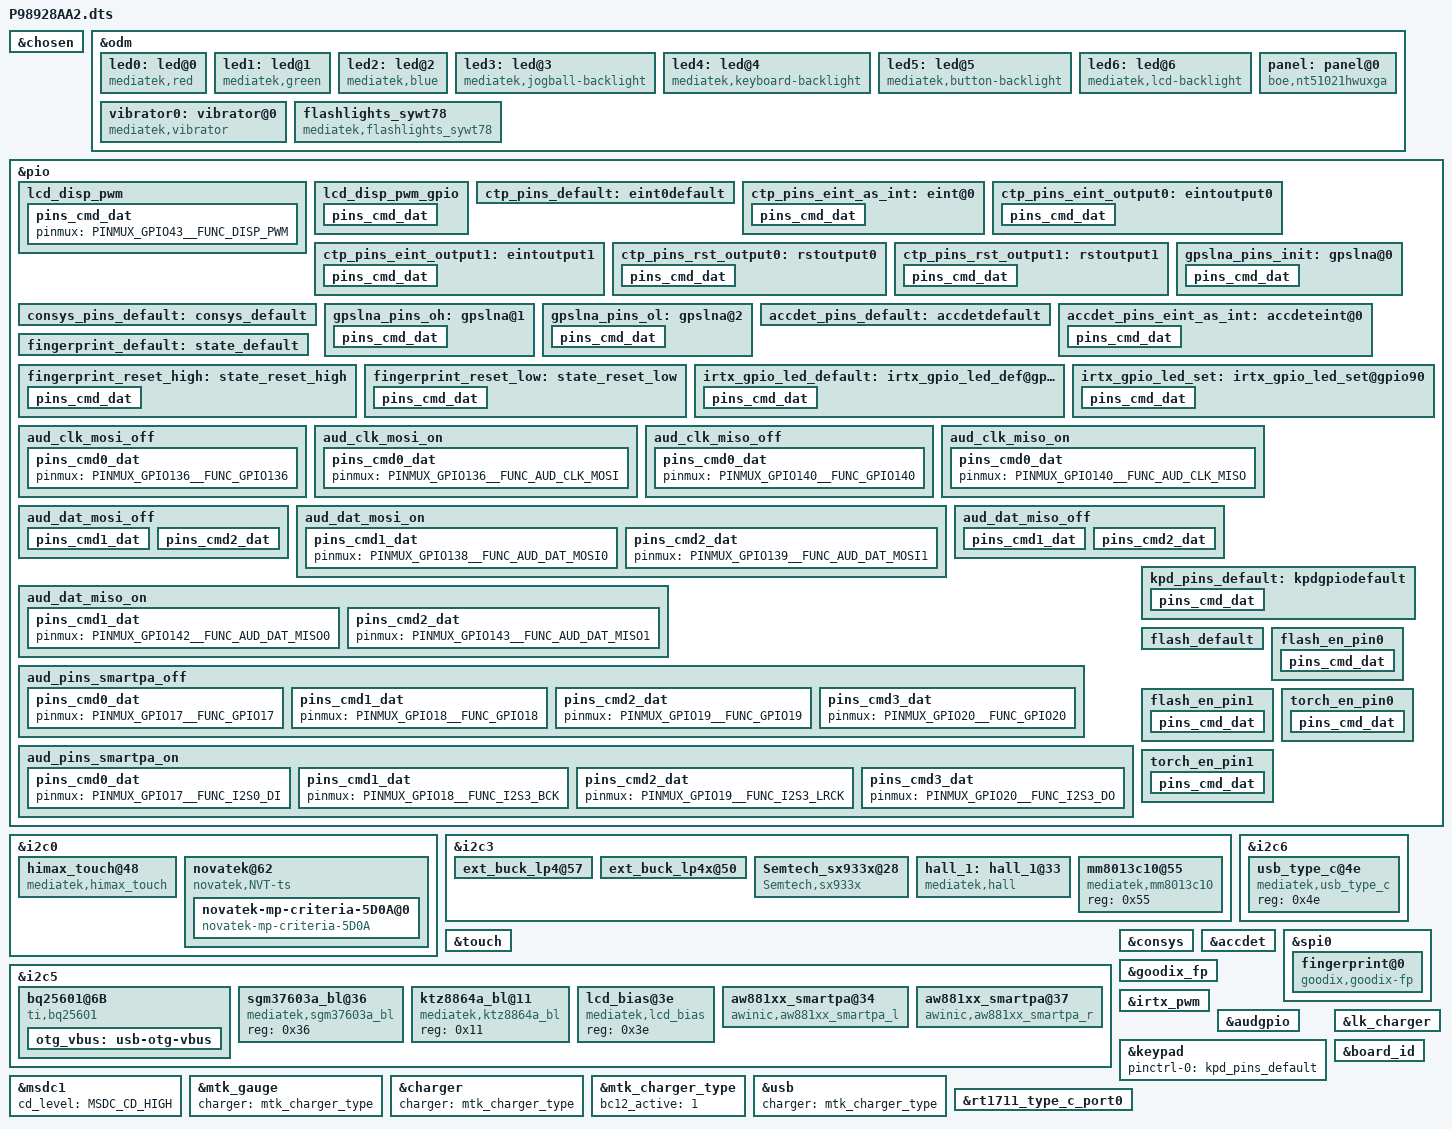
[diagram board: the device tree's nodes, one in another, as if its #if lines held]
// SPDX-License-Identifier: GPL-2.0+
/*
 * Copyright (c) 2019 MediaTek Inc.
 *
 */

#include <dt-bindings/interrupt-controller/arm-gic.h>
#include <dt-bindings/interrupt-controller/irq.h>
#include <dt-bindings/pinctrl/mt6765-pinfunc.h>
#include <dt-bindings/clock/mt6765-clk.h>
#include <dt-bindings/mmc/mt6765-msdc.h>

/dts-v1/;
/plugin/;

/* chosen */
&chosen {

	/* fpga may has no lk, we need to specify display info here */
	/* fb buffer is reserved using this dts by memory node above */
	atag,videolfb-fb_base_h = <0x0>;
	atag,videolfb-fb_base_l = <0x5e605000>;
	atag,videolfb-islcmfound = <1>;
	/* because no lk, so lcm is not inited */
	atag,videolfb-islcm_inited = <0>;
	atag,videolfb-fps= <6000>;
	atag,videolfb-vramSize= <0x017bb000>;
	atag,videolfb-lcmname= "nt35695B_fhd_dsi_cmd_auo_rt5081_drv";
};

&odm {
	led0:led@0 {
		compatible = "mediatek,red";
		led_mode = <0>;
		data = <1>;
		pwm_config = <0 0 0 0 0>;
	};
	led1:led@1 {
		compatible = "mediatek,green";
		led_mode = <0>;
		data = <1>;
		pwm_config = <0 0 0 0 0>;
	};
	led2:led@2 {
		compatible = "mediatek,blue";
		led_mode = <0>;
		data = <1>;
		pwm_config = <0 0 0 0 0>;
	};
	led3:led@3 {
		compatible = "mediatek,jogball-backlight";
		led_mode = <0>;
		data = <1>;
		pwm_config = <0 0 0 0 0>;
	};
	led4:led@4 {
		compatible = "mediatek,keyboard-backlight";
		led_mode = <0>;
		data = <1>;
		pwm_config = <0 0 0 0 0>;
	};
	led5:led@5 {
		compatible = "mediatek,button-backlight";
		led_mode = <0>;
		data = <1>;
		pwm_config = <0 0 0 0 0>;
	};
	led6:led@6 {
		compatible = "mediatek,lcd-backlight";
		led_mode = <5>;
		data = <1>;
		pwm_config = <0 0 0 0 0>;
	};
	panel: panel@0 {
		compatible = "boe,nt51021hwuxga";
		gpio_lcd_rst = <&pio 45 0>;
		gpio_lcd_led_en = <&pio 154 0>;
		gpio_lcd_pwr_enp = <&pio 167 0>;
		gpio_lcd_pwr_enn = <&pio 168 0>;
		pinctrl-names = "disp_pwm", "disp_pwm_gpio";
		pinctrl-0 = <&lcd_disp_pwm>;
		pinctrl-1 = <&lcd_disp_pwm_gpio>;
	};
	vibrator0:vibrator@0 {
		compatible = "mediatek,vibrator";
		vib_timer = <25>;
		vib_limit = <9>;
		vib_vol= <9>;
	};
};

&pio {
	lcd_disp_pwm: lcd_disp_pwm {
		pins_cmd_dat {
			pinmux = <PINMUX_GPIO43__FUNC_DISP_PWM>;
		};
	};

	lcd_disp_pwm_gpio: lcd_disp_pwm_gpio {
		pins_cmd_dat {
			pinmux = <PINMUX_GPIO43__FUNC_GPIO43>;
			output-low;
		};
	};
};

&i2c0 {
	/*cap_touch@38 {
		compatible = "mediatek,cap_touch" ;
		reg = < 0x38 > ;
		status = "okay" ;
	};*/
	himax_touch@48 {
  	compatible = "mediatek,himax_touch";
 	 reg = < 0x48 > ;
 	tpd-resolution = <1080 2160>;
 	use-tpd-button = <1>;
 	tpd-key-num = <3>;
 	tpd-key-local= <139 172 158 0>;
 	tpd-key-dim-local = <180 2400 100 40 860
    		2400 100 40 540 2400 100 40 540 2400 100 40 0 0 0 0>;
 	tpd-max-touch-num = <10>;
 	tpd-filter-enable = <1>;
 	tpd-filter-pixel-density = <168>;
 	tpd-filter-custom-prameters = <0 0 0 0 0 0 0 0 0 0 0 0>;
 	tpd-filter-custom-speed = <0 0 0>;
		status = "okay" ;
	};
/* Novatek device tree node */
	novatek@62 {
		compatible = "novatek,NVT-ts";
		reg = <0x62>;
		status = "ok";
		//vdd-supply = <&pm8994_lvs2>;    //VDDIO
		//avdd-supply = <&pm8994_l22>;    //VDD
		novatek,reset-gpio = <&pio 172 0x00>;
		novatek,irq-gpio = <&pio 10 0x2001>;
		novatek,pen-support;
		novatek,wgp-stylus;
		/* MP */
		//novatek,mp-support-dt;
		novatek-mp-criteria-5D0A@0 {
			#address-cells = <1>;
			#size-cells = <0>;
			compatible = "novatek-mp-criteria-5D0A";
			/* MP Config */
			IC_X_CFG_SIZE = <32>;
			IC_Y_CFG_SIZE = <48>;
			IC_KEY_CFG_SIZE = <4>;
			X_Channel = <32>;
			Y_Channel = <48>;
			AIN_X = <0 1 2 3 4 5 6 7 8 9 10 11 12 13 14 15 16 17 18 19 20 21 22 23 24 25 26 27 28 29 30 31>;
			AIN_Y = <0 1 2 3 4 5 6 7 8 9 10 11 12 13 14 15 16 17 18 19 20 21 22 23 24 25 26 27 28 29 30 31 32 33 34 35 36 37 38 39 40 41 42 43 44 45 46 47>;
			AIN_KEY = <0 1 2 0xFF>;
			/* MP Criteria */
			PS_Config_Lmt_Short_Rawdata_P = <
				14008 14008 14008 14008 14008 14008 14008 14008 14008 14008 14008 14008 14008 14008 14008 14008 14008 14008 14008 14008 14008 14008 14008 14008 14008 14008 14008 14008 14008 14008 14008 14008
				14008 14008 14008 14008 14008 14008 14008 14008 14008 14008 14008 14008 14008 14008 14008 14008 14008 14008 14008 14008 14008 14008 14008 14008 14008 14008 14008 14008 14008 14008 14008 14008
				14008 14008 14008 14008 14008 14008 14008 14008 14008 14008 14008 14008 14008 14008 14008 14008 14008 14008 14008 14008 14008 14008 14008 14008 14008 14008 14008 14008 14008 14008 14008 14008
				14008 14008 14008 14008 14008 14008 14008 14008 14008 14008 14008 14008 14008 14008 14008 14008 14008 14008 14008 14008 14008 14008 14008 14008 14008 14008 14008 14008 14008 14008 14008 14008
				14008 14008 14008 14008 14008 14008 14008 14008 14008 14008 14008 14008 14008 14008 14008 14008 14008 14008 14008 14008 14008 14008 14008 14008 14008 14008 14008 14008 14008 14008 14008 14008
				14008 14008 14008 14008 14008 14008 14008 14008 14008 14008 14008 14008 14008 14008 14008 14008 14008 14008 14008 14008 14008 14008 14008 14008 14008 14008 14008 14008 14008 14008 14008 14008
				14008 14008 14008 14008 14008 14008 14008 14008 14008 14008 14008 14008 14008 14008 14008 14008 14008 14008 14008 14008 14008 14008 14008 14008 14008 14008 14008 14008 14008 14008 14008 14008
				14008 14008 14008 14008 14008 14008 14008 14008 14008 14008 14008 14008 14008 14008 14008 14008 14008 14008 14008 14008 14008 14008 14008 14008 14008 14008 14008 14008 14008 14008 14008 14008
				14008 14008 14008 14008 14008 14008 14008 14008 14008 14008 14008 14008 14008 14008 14008 14008 14008 14008 14008 14008 14008 14008 14008 14008 14008 14008 14008 14008 14008 14008 14008 14008
				14008 14008 14008 14008 14008 14008 14008 14008 14008 14008 14008 14008 14008 14008 14008 14008 14008 14008 14008 14008 14008 14008 14008 14008 14008 14008 14008 14008 14008 14008 14008 14008
				14008 14008 14008 14008 14008 14008 14008 14008 14008 14008 14008 14008 14008 14008 14008 14008 14008 14008 14008 14008 14008 14008 14008 14008 14008 14008 14008 14008 14008 14008 14008 14008
				14008 14008 14008 14008 14008 14008 14008 14008 14008 14008 14008 14008 14008 14008 14008 14008 14008 14008 14008 14008 14008 14008 14008 14008 14008 14008 14008 14008 14008 14008 14008 14008
				14008 14008 14008 14008 14008 14008 14008 14008 14008 14008 14008 14008 14008 14008 14008 14008 14008 14008 14008 14008 14008 14008 14008 14008 14008 14008 14008 14008 14008 14008 14008 14008
				14008 14008 14008 14008 14008 14008 14008 14008 14008 14008 14008 14008 14008 14008 14008 14008 14008 14008 14008 14008 14008 14008 14008 14008 14008 14008 14008 14008 14008 14008 14008 14008
				14008 14008 14008 14008 14008 14008 14008 14008 14008 14008 14008 14008 14008 14008 14008 14008 14008 14008 14008 14008 14008 14008 14008 14008 14008 14008 14008 14008 14008 14008 14008 14008
				14008 14008 14008 14008 14008 14008 14008 14008 14008 14008 14008 14008 14008 14008 14008 14008 14008 14008 14008 14008 14008 14008 14008 14008 14008 14008 14008 14008 14008 14008 14008 14008
				14008 14008 14008 14008 14008 14008 14008 14008 14008 14008 14008 14008 14008 14008 14008 14008 14008 14008 14008 14008 14008 14008 14008 14008 14008 14008 14008 14008 14008 14008 14008 14008
				14008 14008 14008 14008 14008 14008 14008 14008 14008 14008 14008 14008 14008 14008 14008 14008 14008 14008 14008 14008 14008 14008 14008 14008 14008 14008 14008 14008 14008 14008 14008 14008
				14008 14008 14008 14008 14008 14008 14008 14008 14008 14008 14008 14008 14008 14008 14008 14008 14008 14008 14008 14008 14008 14008 14008 14008 14008 14008 14008 14008 14008 14008 14008 14008
				14008 14008 14008 14008 14008 14008 14008 14008 14008 14008 14008 14008 14008 14008 14008 14008 14008 14008 14008 14008 14008 14008 14008 14008 14008 14008 14008 14008 14008 14008 14008 14008
				14008 14008 14008 14008 14008 14008 14008 14008 14008 14008 14008 14008 14008 14008 14008 14008 14008 14008 14008 14008 14008 14008 14008 14008 14008 14008 14008 14008 14008 14008 14008 14008
				14008 14008 14008 14008 14008 14008 14008 14008 14008 14008 14008 14008 14008 14008 14008 14008 14008 14008 14008 14008 14008 14008 14008 14008 14008 14008 14008 14008 14008 14008 14008 14008
				14008 14008 14008 14008 14008 14008 14008 14008 14008 14008 14008 14008 14008 14008 14008 14008 14008 14008 14008 14008 14008 14008 14008 14008 14008 14008 14008 14008 14008 14008 14008 14008
				14008 14008 14008 14008 14008 14008 14008 14008 14008 14008 14008 14008 14008 14008 14008 14008 14008 14008 14008 14008 14008 14008 14008 14008 14008 14008 14008 14008 14008 14008 14008 14008
				14008 14008 14008 14008 14008 14008 14008 14008 14008 14008 14008 14008 14008 14008 14008 14008 14008 14008 14008 14008 14008 14008 14008 14008 14008 14008 14008 14008 14008 14008 14008 14008
				14008 14008 14008 14008 14008 14008 14008 14008 14008 14008 14008 14008 14008 14008 14008 14008 14008 14008 14008 14008 14008 14008 14008 14008 14008 14008 14008 14008 14008 14008 14008 14008
				14008 14008 14008 14008 14008 14008 14008 14008 14008 14008 14008 14008 14008 14008 14008 14008 14008 14008 14008 14008 14008 14008 14008 14008 14008 14008 14008 14008 14008 14008 14008 14008
				14008 14008 14008 14008 14008 14008 14008 14008 14008 14008 14008 14008 14008 14008 14008 14008 14008 14008 14008 14008 14008 14008 14008 14008 14008 14008 14008 14008 14008 14008 14008 14008
				14008 14008 14008 14008 14008 14008 14008 14008 14008 14008 14008 14008 14008 14008 14008 14008 14008 14008 14008 14008 14008 14008 14008 14008 14008 14008 14008 14008 14008 14008 14008 14008
				14008 14008 14008 14008 14008 14008 14008 14008 14008 14008 14008 14008 14008 14008 14008 14008 14008 14008 14008 14008 14008 14008 14008 14008 14008 14008 14008 14008 14008 14008 14008 14008
				14008 14008 14008 14008 14008 14008 14008 14008 14008 14008 14008 14008 14008 14008 14008 14008 14008 14008 14008 14008 14008 14008 14008 14008 14008 14008 14008 14008 14008 14008 14008 14008
				14008 14008 14008 14008 14008 14008 14008 14008 14008 14008 14008 14008 14008 14008 14008 14008 14008 14008 14008 14008 14008 14008 14008 14008 14008 14008 14008 14008 14008 14008 14008 14008
				14008 14008 14008 14008 14008 14008 14008 14008 14008 14008 14008 14008 14008 14008 14008 14008 14008 14008 14008 14008 14008 14008 14008 14008 14008 14008 14008 14008 14008 14008 14008 14008
				14008 14008 14008 14008 14008 14008 14008 14008 14008 14008 14008 14008 14008 14008 14008 14008 14008 14008 14008 14008 14008 14008 14008 14008 14008 14008 14008 14008 14008 14008 14008 14008
				14008 14008 14008 14008 14008 14008 14008 14008 14008 14008 14008 14008 14008 14008 14008 14008 14008 14008 14008 14008 14008 14008 14008 14008 14008 14008 14008 14008 14008 14008 14008 14008
				14008 14008 14008 14008 14008 14008 14008 14008 14008 14008 14008 14008 14008 14008 14008 14008 14008 14008 14008 14008 14008 14008 14008 14008 14008 14008 14008 14008 14008 14008 14008 14008
				14008 14008 14008 14008 14008 14008 14008 14008 14008 14008 14008 14008 14008 14008 14008 14008 14008 14008 14008 14008 14008 14008 14008 14008 14008 14008 14008 14008 14008 14008 14008 14008
				14008 14008 14008 14008 14008 14008 14008 14008 14008 14008 14008 14008 14008 14008 14008 14008 14008 14008 14008 14008 14008 14008 14008 14008 14008 14008 14008 14008 14008 14008 14008 14008
				14008 14008 14008 14008 14008 14008 14008 14008 14008 14008 14008 14008 14008 14008 14008 14008 14008 14008 14008 14008 14008 14008 14008 14008 14008 14008 14008 14008 14008 14008 14008 14008
				14008 14008 14008 14008 14008 14008 14008 14008 14008 14008 14008 14008 14008 14008 14008 14008 14008 14008 14008 14008 14008 14008 14008 14008 14008 14008 14008 14008 14008 14008 14008 14008
				14008 14008 14008 14008 14008 14008 14008 14008 14008 14008 14008 14008 14008 14008 14008 14008 14008 14008 14008 14008 14008 14008 14008 14008 14008 14008 14008 14008 14008 14008 14008 14008
				14008 14008 14008 14008 14008 14008 14008 14008 14008 14008 14008 14008 14008 14008 14008 14008 14008 14008 14008 14008 14008 14008 14008 14008 14008 14008 14008 14008 14008 14008 14008 14008
				14008 14008 14008 14008 14008 14008 14008 14008 14008 14008 14008 14008 14008 14008 14008 14008 14008 14008 14008 14008 14008 14008 14008 14008 14008 14008 14008 14008 14008 14008 14008 14008
				14008 14008 14008 14008 14008 14008 14008 14008 14008 14008 14008 14008 14008 14008 14008 14008 14008 14008 14008 14008 14008 14008 14008 14008 14008 14008 14008 14008 14008 14008 14008 14008
				14008 14008 14008 14008 14008 14008 14008 14008 14008 14008 14008 14008 14008 14008 14008 14008 14008 14008 14008 14008 14008 14008 14008 14008 14008 14008 14008 14008 14008 14008 14008 14008
				14008 14008 14008 14008 14008 14008 14008 14008 14008 14008 14008 14008 14008 14008 14008 14008 14008 14008 14008 14008 14008 14008 14008 14008 14008 14008 14008 14008 14008 14008 14008 14008
				14008 14008 14008 14008 14008 14008 14008 14008 14008 14008 14008 14008 14008 14008 14008 14008 14008 14008 14008 14008 14008 14008 14008 14008 14008 14008 14008 14008 14008 14008 14008 14008
				14008 14008 14008 14008 14008 14008 14008 14008 14008 14008 14008 14008 14008 14008 14008 14008 14008 14008 14008 14008 14008 14008 14008 14008 14008 14008 14008 14008 14008 14008 14008 14008
				14008 14008 14008>;

			PS_Config_Lmt_Short_Rawdata_N = <
				10100 10100 10100 10100 10100 10100 10100 10100 10100 10100 10100 10100 10100 10100 10100 10100 10100 10100 10100 10100 10100 10100 10100 10100 10100 10100 10100 10100 10100 10100 10100 10100
				10100 10100 10100 10100 10100 10100 10100 10100 10100 10100 10100 10100 10100 10100 10100 10100 10100 10100 10100 10100 10100 10100 10100 10100 10100 10100 10100 10100 10100 10100 10100 10100
				10100 10100 10100 10100 10100 10100 10100 10100 10100 10100 10100 10100 10100 10100 10100 10100 10100 10100 10100 10100 10100 10100 10100 10100 10100 10100 10100 10100 10100 10100 10100 10100
				10100 10100 10100 10100 10100 10100 10100 10100 10100 10100 10100 10100 10100 10100 10100 10100 10100 10100 10100 10100 10100 10100 10100 10100 10100 10100 10100 10100 10100 10100 10100 10100
				10100 10100 10100 10100 10100 10100 10100 10100 10100 10100 10100 10100 10100 10100 10100 10100 10100 10100 10100 10100 10100 10100 10100 10100 10100 10100 10100 10100 10100 10100 10100 10100
				10100 10100 10100 10100 10100 10100 10100 10100 10100 10100 10100 10100 10100 10100 10100 10100 10100 10100 10100 10100 10100 10100 10100 10100 10100 10100 10100 10100 10100 10100 10100 10100
				10100 10100 10100 10100 10100 10100 10100 10100 10100 10100 10100 10100 10100 10100 10100 10100 10100 10100 10100 10100 10100 10100 10100 10100 10100 10100 10100 10100 10100 10100 10100 10100
				10100 10100 10100 10100 10100 10100 10100 10100 10100 10100 10100 10100 10100 10100 10100 10100 10100 10100 10100 10100 10100 10100 10100 10100 10100 10100 10100 10100 10100 10100 10100 10100
				10100 10100 10100 10100 10100 10100 10100 10100 10100 10100 10100 10100 10100 10100 10100 10100 10100 10100 10100 10100 10100 10100 10100 10100 10100 10100 10100 10100 10100 10100 10100 10100
				10100 10100 10100 10100 10100 10100 10100 10100 10100 10100 10100 10100 10100 10100 10100 10100 10100 10100 10100 10100 10100 10100 10100 10100 10100 10100 10100 10100 10100 10100 10100 10100
				10100 10100 10100 10100 10100 10100 10100 10100 10100 10100 10100 10100 10100 10100 10100 10100 10100 10100 10100 10100 10100 10100 10100 10100 10100 10100 10100 10100 10100 10100 10100 10100
				10100 10100 10100 10100 10100 10100 10100 10100 10100 10100 10100 10100 10100 10100 10100 10100 10100 10100 10100 10100 10100 10100 10100 10100 10100 10100 10100 10100 10100 10100 10100 10100
				10100 10100 10100 10100 10100 10100 10100 10100 10100 10100 10100 10100 10100 10100 10100 10100 10100 10100 10100 10100 10100 10100 10100 10100 10100 10100 10100 10100 10100 10100 10100 10100
				10100 10100 10100 10100 10100 10100 10100 10100 10100 10100 10100 10100 10100 10100 10100 10100 10100 10100 10100 10100 10100 10100 10100 10100 10100 10100 10100 10100 10100 10100 10100 10100
				10100 10100 10100 10100 10100 10100 10100 10100 10100 10100 10100 10100 10100 10100 10100 10100 10100 10100 10100 10100 10100 10100 10100 10100 10100 10100 10100 10100 10100 10100 10100 10100
				10100 10100 10100 10100 10100 10100 10100 10100 10100 10100 10100 10100 10100 10100 10100 10100 10100 10100 10100 10100 10100 10100 10100 10100 10100 10100 10100 10100 10100 10100 10100 10100
				10100 10100 10100 10100 10100 10100 10100 10100 10100 10100 10100 10100 10100 10100 10100 10100 10100 10100 10100 10100 10100 10100 10100 10100 10100 10100 10100 10100 10100 10100 10100 10100
				10100 10100 10100 10100 10100 10100 10100 10100 10100 10100 10100 10100 10100 10100 10100 10100 10100 10100 10100 10100 10100 10100 10100 10100 10100 10100 10100 10100 10100 10100 10100 10100
				10100 10100 10100 10100 10100 10100 10100 10100 10100 10100 10100 10100 10100 10100 10100 10100 10100 10100 10100 10100 10100 10100 10100 10100 10100 10100 10100 10100 10100 10100 10100 10100
				10100 10100 10100 10100 10100 10100 10100 10100 10100 10100 10100 10100 10100 10100 10100 10100 10100 10100 10100 10100 10100 10100 10100 10100 10100 10100 10100 10100 10100 10100 10100 10100
				10100 10100 10100 10100 10100 10100 10100 10100 10100 10100 10100 10100 10100 10100 10100 10100 10100 10100 10100 10100 10100 10100 10100 10100 10100 10100 10100 10100 10100 10100 10100 10100
				10100 10100 10100 10100 10100 10100 10100 10100 10100 10100 10100 10100 10100 10100 10100 10100 10100 10100 10100 10100 10100 10100 10100 10100 10100 10100 10100 10100 10100 10100 10100 10100
				10100 10100 10100 10100 10100 10100 10100 10100 10100 10100 10100 10100 10100 10100 10100 10100 10100 10100 10100 10100 10100 10100 10100 10100 10100 10100 10100 10100 10100 10100 10100 10100
				10100 10100 10100 10100 10100 10100 10100 10100 10100 10100 10100 10100 10100 10100 10100 10100 10100 10100 10100 10100 10100 10100 10100 10100 10100 10100 10100 10100 10100 10100 10100 10100
				10100 10100 10100 10100 10100 10100 10100 10100 10100 10100 10100 10100 10100 10100 10100 10100 10100 10100 10100 10100 10100 10100 10100 10100 10100 10100 10100 10100 10100 10100 10100 10100
				10100 10100 10100 10100 10100 10100 10100 10100 10100 10100 10100 10100 10100 10100 10100 10100 10100 10100 10100 10100 10100 10100 10100 10100 10100 10100 10100 10100 10100 10100 10100 10100
				10100 10100 10100 10100 10100 10100 10100 10100 10100 10100 10100 10100 10100 10100 10100 10100 10100 10100 10100 10100 10100 10100 10100 10100 10100 10100 10100 10100 10100 10100 10100 10100
				10100 10100 10100 10100 10100 10100 10100 10100 10100 10100 10100 10100 10100 10100 10100 10100 10100 10100 10100 10100 10100 10100 10100 10100 10100 10100 10100 10100 10100 10100 10100 10100
				10100 10100 10100 10100 10100 10100 10100 10100 10100 10100 10100 10100 10100 10100 10100 10100 10100 10100 10100 10100 10100 10100 10100 10100 10100 10100 10100 10100 10100 10100 10100 10100
				10100 10100 10100 10100 10100 10100 10100 10100 10100 10100 10100 10100 10100 10100 10100 10100 10100 10100 10100 10100 10100 10100 10100 10100 10100 10100 10100 10100 10100 10100 10100 10100
				10100 10100 10100 10100 10100 10100 10100 10100 10100 10100 10100 10100 10100 10100 10100 10100 10100 10100 10100 10100 10100 10100 10100 10100 10100 10100 10100 10100 10100 10100 10100 10100
				10100 10100 10100 10100 10100 10100 10100 10100 10100 10100 10100 10100 10100 10100 10100 10100 10100 10100 10100 10100 10100 10100 10100 10100 10100 10100 10100 10100 10100 10100 10100 10100
				10100 10100 10100 10100 10100 10100 10100 10100 10100 10100 10100 10100 10100 10100 10100 10100 10100 10100 10100 10100 10100 10100 10100 10100 10100 10100 10100 10100 10100 10100 10100 10100
				10100 10100 10100 10100 10100 10100 10100 10100 10100 10100 10100 10100 10100 10100 10100 10100 10100 10100 10100 10100 10100 10100 10100 10100 10100 10100 10100 10100 10100 10100 10100 10100
				10100 10100 10100 10100 10100 10100 10100 10100 10100 10100 10100 10100 10100 10100 10100 10100 10100 10100 10100 10100 10100 10100 10100 10100 10100 10100 10100 10100 10100 10100 10100 10100
				10100 10100 10100 10100 10100 10100 10100 10100 10100 10100 10100 10100 10100 10100 10100 10100 10100 10100 10100 10100 10100 10100 10100 10100 10100 10100 10100 10100 10100 10100 10100 10100
				10100 10100 10100 10100 10100 10100 10100 10100 10100 10100 10100 10100 10100 10100 10100 10100 10100 10100 10100 10100 10100 10100 10100 10100 10100 10100 10100 10100 10100 10100 10100 10100
				10100 10100 10100 10100 10100 10100 10100 10100 10100 10100 10100 10100 10100 10100 10100 10100 10100 10100 10100 10100 10100 10100 10100 10100 10100 10100 10100 10100 10100 10100 10100 10100
				10100 10100 10100 10100 10100 10100 10100 10100 10100 10100 10100 10100 10100 10100 10100 10100 10100 10100 10100 10100 10100 10100 10100 10100 10100 10100 10100 10100 10100 10100 10100 10100
				10100 10100 10100 10100 10100 10100 10100 10100 10100 10100 10100 10100 10100 10100 10100 10100 10100 10100 10100 10100 10100 10100 10100 10100 10100 10100 10100 10100 10100 10100 10100 10100
				10100 10100 10100 10100 10100 10100 10100 10100 10100 10100 10100 10100 10100 10100 10100 10100 10100 10100 10100 10100 10100 10100 10100 10100 10100 10100 10100 10100 10100 10100 10100 10100
				10100 10100 10100 10100 10100 10100 10100 10100 10100 10100 10100 10100 10100 10100 10100 10100 10100 10100 10100 10100 10100 10100 10100 10100 10100 10100 10100 10100 10100 10100 10100 10100
				10100 10100 10100 10100 10100 10100 10100 10100 10100 10100 10100 10100 10100 10100 10100 10100 10100 10100 10100 10100 10100 10100 10100 10100 10100 10100 10100 10100 10100 10100 10100 10100
				10100 10100 10100 10100 10100 10100 10100 10100 10100 10100 10100 10100 10100 10100 10100 10100 10100 10100 10100 10100 10100 10100 10100 10100 10100 10100 10100 10100 10100 10100 10100 10100
				10100 10100 10100 10100 10100 10100 10100 10100 10100 10100 10100 10100 10100 10100 10100 10100 10100 10100 10100 10100 10100 10100 10100 10100 10100 10100 10100 10100 10100 10100 10100 10100
				10100 10100 10100 10100 10100 10100 10100 10100 10100 10100 10100 10100 10100 10100 10100 10100 10100 10100 10100 10100 10100 10100 10100 10100 10100 10100 10100 10100 10100 10100 10100 10100
				10100 10100 10100 10100 10100 10100 10100 10100 10100 10100 10100 10100 10100 10100 10100 10100 10100 10100 10100 10100 10100 10100 10100 10100 10100 10100 10100 10100 10100 10100 10100 10100
				10100 10100 10100 10100 10100 10100 10100 10100 10100 10100 10100 10100 10100 10100 10100 10100 10100 10100 10100 10100 10100 10100 10100 10100 10100 10100 10100 10100 10100 10100 10100 10100
				10100 10100 10100>;

			PS_Config_Lmt_Open_Rawdata_P = <
				3662 3628 3626 3553 3704 3627 3549 3435 3136 3276 3319 3375 3409 3484 3619 3659 3637 3581 3564 3518 3518 3479 3431 3312 3141 3267 3304 3334 3319 3427 3488 3609
				3676 3658 3634 3593 3666 3554 3500 3414 3131 3227 3263 3334 3396 3502 3556 3635 3640 3610 3588 3568 3474 3431 3360 3274 3108 3217 3243 3332 3294 3420 3441 3514
				3715 3679 3556 3588 3619 3641 3553 3491 3155 3273 3346 3403 3462 3500 3581 3697 3679 3616 3502 3522 3509 3481 3425 3365 3124 3295 3337 3392 3355 3409 3509 3578
				3649 3696 3586 3598 3662 3617 3486 3445 3129 3271 3292 3347 3421 3486 3610 3627 3662 3619 3529 3557 3550 3430 3383 3305 3112 3253 3281 3329 3340 3388 3511 3526
				3752 3722 3610 3490 3656 3568 3571 3501 3134 3304 3344 3434 3493 3553 3598 3474 3745 3652 3537 3442 3505 3472 3434 3358 3130 3284 3360 3427 3390 3432 3497 3413
				3729 3652 3624 3518 3672 3621 3563 3432 3196 3263 3333 3369 3423 3514 3579 3682 3655 3641 3542 3459 3540 3508 3392 3330 3158 3262 3305 3350 3323 3421 3466 3592
				3686 3745 3651 3549 3532 3619 3516 3325 3196 3270 3368 3418 3511 3588 3467 3675 3651 3725 3581 3477 3397 3472 3431 3173 3168 3270 3340 3448 3417 3488 3336 3581
				3819 3717 3579 3564 3560 3631 3565 3521 3182 3346 3334 3421 3458 3522 3619 3656 3747 3634 3571 3477 3425 3502 3469 3340 3192 3311 3334 3406 3355 3427 3505 3547
				3747 3680 3677 3588 3595 3449 3544 3476 3260 3336 3339 3458 3509 3574 3694 3731 3669 3655 3647 3522 3441 3334 3417 3381 3239 3319 3337 3427 3448 3479 3582 3607
				3784 3795 3649 3519 3602 3334 3404 3516 3239 3316 3418 3423 3505 3395 3630 3687 3697 3743 3560 3512 3442 3218 3306 3416 3185 3355 3385 3418 3400 3292 3518 3591
				3739 3735 3606 3609 3627 3540 3417 3519 3273 3406 3409 3423 3546 3614 3736 3749 3689 3663 3564 3579 3472 3400 3308 3395 3269 3410 3388 3411 3427 3553 3619 3654
				3791 3766 3712 3586 3374 3554 3445 3535 3259 3375 3383 3508 3312 3605 3658 3682 3718 3690 3668 3500 3281 3396 3332 3424 3213 3353 3414 3466 3231 3502 3542 3578
				3777 3735 3665 3544 3663 3579 3480 3330 3273 3410 3473 3490 3511 3649 3717 3780 3718 3680 3586 3505 3544 3434 3334 3222 3263 3416 3488 3473 3413 3529 3637 3677
				3750 3785 3698 3470 3634 3508 3494 3362 3292 3392 3439 3311 3598 3607 3705 3715 3708 3731 3620 3442 3460 3430 3343 3248 3255 3367 3416 3325 3470 3515 3589 3606
				3801 3771 3662 3557 3600 3613 3523 3395 3270 3404 3474 3522 3578 3607 3754 3771 3760 3731 3606 3494 3469 3498 3385 3253 3238 3414 3493 3514 3469 3511 3623 3705
				3784 3747 3707 3635 3712 3582 3452 3410 3332 3435 3460 3536 3561 3693 3712 3753 3715 3710 3652 3561 3574 3421 3376 3255 3311 3423 3441 3516 3494 3560 3603 3649
				3826 3794 3515 3609 3656 3540 3543 3438 3333 3417 3283 3575 3662 3676 3712 3802 3791 3759 3466 3557 3494 3425 3446 3298 3301 3403 3297 3585 3567 3570 3599 3680
				3764 3775 3677 3652 3686 3647 3521 3365 3315 3472 3504 3547 3623 3648 3795 3750 3728 3740 3637 3596 3521 3514 3362 3285 3302 3460 3490 3526 3508 3581 3655 3656
				3833 3628 3721 3637 3656 3600 3486 3455 3378 3271 3490 3567 3658 3761 3775 3747 3788 3607 3689 3592 3512 3445 3379 3355 3383 3243 3483 3570 3568 3666 3655 3659
				3794 3773 3707 3616 3708 3631 3584 3430 3318 3459 3546 3584 3628 3719 3745 3826 3759 3733 3662 3584 3550 3472 3456 3284 3311 3446 3532 3570 3511 3591 3670 3698
				3784 3848 3761 3658 3694 3610 3553 3400 3421 3525 3547 3570 3648 3757 3837 3806 3742 3819 3738 3626 3557 3470 3397 3297 3388 3535 3523 3563 3553 3673 3726 3700
				3679 3808 3696 3642 3676 3658 3581 3491 3158 3470 3530 3634 3676 3725 3798 3785 3603 3773 3666 3606 3540 3509 3424 3375 3137 3467 3530 3624 3567 3609 3665 3718
				3843 3803 3774 3693 3722 3640 3558 3462 3432 3585 3603 3640 3661 3750 3834 3880 3801 3778 3742 3669 3584 3518 3424 3312 3416 3542 3612 3623 3551 3662 3743 3792
				3838 3876 3735 3637 3708 3623 3598 3480 3396 3501 3537 3614 3715 3774 3802 3827 3745 3824 3701 3612 3567 3497 3453 3333 3379 3484 3550 3616 3603 3669 3683 3705
				3852 3850 3735 3711 3754 3661 3585 3463 3439 3581 3659 3690 3725 3757 3822 3862 3794 3822 3707 3684 3633 3533 3470 3326 3418 3568 3631 3710 3603 3644 3736 3791
				3847 3840 3803 3669 3689 3645 3567 3500 3403 3535 3570 3621 3698 3816 3836 3824 3778 3763 3757 3642 3568 3514 3459 3361 3404 3502 3561 3634 3589 3707 3739 3711
				3910 3862 3801 3668 3773 3694 3606 3488 3424 3582 3652 3745 3774 3815 3816 3848 3848 3820 3767 3635 3641 3568 3498 3371 3414 3551 3648 3712 3684 3690 3705 3764
				3827 3855 3788 3735 3733 3637 3598 3472 3459 3542 3607 3647 3700 3784 3882 3871 3768 3796 3717 3686 3603 3529 3486 3353 3474 3539 3602 3641 3614 3672 3780 3766
				3935 3918 3815 3736 3736 3721 3647 3507 3467 3567 3655 3743 3834 3861 3876 3845 3876 3879 3778 3711 3603 3592 3547 3397 3448 3551 3647 3736 3686 3777 3750 3759
				3848 3838 3808 3731 3808 3670 3584 3493 3553 3600 3619 3690 3731 3785 3844 3907 3798 3794 3757 3662 3654 3553 3479 3374 3525 3607 3633 3677 3620 3684 3736 3813
				3885 3936 3868 3753 3803 3677 3669 3543 3521 3610 3644 3736 3833 3924 3918 3904 3827 3904 3826 3710 3656 3554 3546 3425 3512 3585 3651 3729 3715 3774 3840 3788
				3939 3857 3796 3740 3792 3742 3624 3490 3476 3696 3679 3697 3773 3806 3844 3869 3858 3813 3753 3690 3617 3603 3516 3386 3467 3661 3707 3721 3656 3696 3757 3768
				3899 3889 3885 3792 3817 3746 3630 3563 3546 3663 3686 3724 3816 3908 3980 3943 3827 3838 3855 3757 3673 3603 3505 3445 3560 3645 3669 3726 3697 3780 3833 3886
				3893 3942 3816 3728 3808 3738 3690 3518 3483 3616 3780 3764 3781 3847 3866 3869 3845 3866 3785 3698 3656 3565 3551 3424 3484 3596 3761 3792 3690 3728 3753 3792
				3879 3908 3858 3813 3875 3768 3703 3528 3514 3684 3752 3771 3809 3886 3973 4009 3855 3854 3803 3785 3718 3623 3571 3423 3491 3687 3746 3752 3700 3768 3850 3879
				3896 3903 3907 3753 3802 3750 3693 3584 3462 3631 3693 3864 3850 3852 3913 3893 3850 3872 3843 3722 3656 3609 3533 3449 3428 3630 3693 3844 3760 3756 3788 3794
				3922 3883 3872 3802 3893 3813 3728 3593 3512 3599 3766 3841 3858 3880 3949 4002 3911 3878 3836 3757 3749 3663 3589 3481 3536 3579 3794 3826 3722 3771 3836 3900
				3914 3901 3864 3844 3824 3742 3701 3588 3501 3549 3704 3775 3962 3918 3908 3941 3873 3852 3847 3784 3680 3605 3567 3435 3469 3511 3715 3771 3816 3826 3823 3822
				3990 3922 3841 3809 3871 3824 3761 3614 3549 3598 3669 3852 3931 3918 3938 3973 3960 3922 3847 3770 3710 3684 3619 3493 3535 3624 3654 3869 3792 3784 3823 3869
				3931 3911 3866 3795 3917 3767 3701 3588 3498 3585 3617 3784 3852 4016 3977 3935 3896 3890 3836 3784 3738 3623 3577 3466 3488 3550 3589 3794 3733 3872 3887 3859
				4006 3998 3886 3781 3893 3817 3780 3651 3515 3626 3668 3745 3931 3987 3976 3964 3977 3971 3900 3795 3731 3665 3654 3529 3549 3620 3696 3735 3830 3843 3850 3850
				3927 3941 3876 3808 3883 3864 3728 3591 3553 3575 3656 3691 3865 3908 4081 4002 3901 3918 3866 3791 3745 3686 3595 3469 3532 3567 3627 3673 3752 3791 3936 3914
				4037 4006 3960 3833 3864 3834 3778 3668 3544 3596 3703 3750 3830 3992 4044 3999 3953 3984 3948 3851 3754 3682 3634 3546 3537 3621 3690 3787 3694 3882 3920 3861
				3977 3925 3903 3820 3889 3822 3813 3617 3532 3631 3648 3736 3777 3922 3970 4113 3917 3914 3886 3820 3740 3698 3655 3501 3518 3621 3649 3707 3631 3802 3858 3945
				3938 4026 3964 3906 3907 3799 3778 3663 3610 3620 3673 3789 3837 3942 4058 4075 3932 3973 3957 3900 3806 3696 3638 3537 3568 3613 3712 3785 3740 3803 3956 3924
				3976 3974 3885 3845 3901 3820 3775 3700 3568 3606 3707 3726 3823 3880 3984 3994 3978 3922 3899 3841 3767 3684 3662 3557 3563 3599 3708 3733 3665 3731 3869 3850
				3967 3934 3976 3907 3987 3838 3749 3666 3610 3684 3698 3749 3872 3942 4009 4078 3925 3943 3929 3907 3851 3746 3659 3544 3612 3654 3684 3799 3740 3848 3875 3946
				3973 3974 3942 3843 3932 3844 3780 3668 3560 3634 3684 3775 3815 3927 3956 4006 3959 3991 3908 3851 3795 3719 3658 3577 3554 3633 3672 3788 3689 3780 3809 3865
				5120 5120 5120>;

			PS_Config_Lmt_Open_Rawdata_N = <
				1569 1555 1554 1522 1587 1554 1521 1472 1344 1404 1422 1446 1461 1493 1551 1568 1558 1534 1527 1507 1507 1491 1470 1419 1346 1400 1416 1429 1422 1468 1495 1546
				1575 1567 1557 1540 1571 1523 1500 1463 1342 1383 1398 1429 1455 1501 1524 1558 1560 1547 1537 1529 1489 1470 1440 1403 1332 1378 1390 1428 1411 1465 1474 1506
				1592 1576 1524 1537 1551 1560 1522 1496 1352 1402 1434 1458 1483 1500 1534 1584 1576 1549 1501 1509 1504 1492 1468 1442 1339 1412 1430 1453 1438 1461 1504 1533
				1564 1584 1537 1542 1569 1550 1494 1476 1341 1402 1411 1434 1466 1494 1547 1554 1569 1551 1512 1524 1521 1470 1450 1416 1333 1394 1406 1426 1431 1452 1504 1511
				1608 1595 1547 1495 1567 1529 1530 1500 1343 1416 1433 1471 1497 1522 1542 1489 1605 1565 1516 1475 1502 1488 1471 1439 1341 1407 1440 1468 1453 1471 1498 1462
				1598 1565 1553 1507 1573 1552 1527 1471 1369 1398 1428 1444 1467 1506 1534 1578 1566 1560 1518 1482 1517 1503 1453 1427 1353 1398 1416 1435 1424 1466 1485 1539
				1579 1605 1564 1521 1513 1551 1507 1425 1369 1401 1443 1465 1504 1537 1486 1575 1564 1596 1534 1490 1456 1488 1470 1360 1357 1401 1431 1477 1464 1495 1429 1534
				1636 1593 1534 1527 1525 1556 1528 1509 1363 1434 1429 1466 1482 1509 1551 1567 1606 1557 1530 1490 1468 1501 1486 1431 1368 1419 1429 1459 1438 1468 1502 1520
				1606 1577 1576 1537 1540 1478 1519 1489 1397 1429 1431 1482 1504 1531 1583 1599 1572 1566 1563 1509 1474 1429 1464 1449 1388 1422 1430 1468 1477 1491 1535 1546
				1621 1626 1564 1508 1543 1429 1459 1507 1388 1421 1465 1467 1502 1455 1555 1580 1584 1604 1525 1505 1475 1379 1417 1464 1365 1438 1450 1465 1457 1411 1507 1539
				1602 1600 1545 1546 1554 1517 1464 1508 1402 1459 1461 1467 1519 1549 1601 1606 1581 1570 1527 1534 1488 1457 1417 1455 1401 1461 1452 1462 1468 1522 1551 1566
				1624 1614 1591 1537 1446 1523 1476 1515 1396 1446 1450 1503 1419 1545 1567 1578 1593 1581 1572 1500 1406 1455 1428 1467 1377 1437 1463 1485 1384 1501 1518 1533
				1618 1600 1570 1519 1570 1534 1491 1427 1402 1461 1488 1495 1504 1564 1593 1620 1593 1577 1537 1502 1519 1471 1429 1381 1398 1464 1495 1488 1462 1512 1558 1576
				1607 1622 1585 1487 1557 1503 1497 1441 1411 1453 1474 1419 1542 1546 1588 1592 1589 1599 1551 1475 1483 1470 1432 1392 1395 1443 1464 1425 1487 1506 1538 1545
				1629 1616 1569 1524 1543 1548 1510 1455 1401 1459 1489 1509 1533 1546 1609 1616 1611 1599 1545 1497 1486 1499 1450 1394 1387 1463 1497 1506 1486 1504 1552 1588
				1621 1606 1588 1558 1591 1535 1479 1461 1428 1472 1483 1515 1526 1582 1591 1608 1592 1590 1565 1526 1531 1466 1447 1395 1419 1467 1474 1507 1497 1525 1544 1564
				1639 1626 1506 1546 1567 1517 1518 1473 1428 1464 1407 1532 1569 1575 1591 1629 1624 1611 1485 1524 1497 1468 1477 1413 1414 1458 1413 1536 1528 1530 1542 1577
				1613 1618 1576 1565 1579 1563 1509 1442 1420 1488 1501 1520 1552 1563 1626 1607 1597 1603 1558 1541 1509 1506 1441 1408 1415 1483 1495 1511 1503 1534 1566 1567
				1642 1555 1594 1558 1567 1543 1494 1480 1447 1402 1495 1528 1567 1612 1618 1606 1623 1546 1581 1539 1505 1476 1448 1438 1450 1390 1492 1530 1529 1571 1566 1568
				1626 1617 1588 1549 1589 1556 1536 1470 1422 1482 1519 1536 1555 1594 1605 1639 1611 1600 1569 1536 1521 1488 1481 1407 1419 1477 1513 1530 1504 1539 1573 1585
				1621 1649 1612 1567 1583 1547 1522 1457 1466 1510 1520 1530 1563 1610 1644 1631 1603 1636 1602 1554 1524 1487 1456 1413 1452 1515 1510 1527 1522 1574 1597 1585
				1576 1632 1584 1561 1575 1567 1534 1496 1353 1487 1513 1557 1575 1596 1627 1622 1544 1617 1571 1545 1517 1504 1467 1446 1344 1486 1513 1553 1528 1546 1570 1593
				1647 1630 1617 1582 1595 1560 1525 1483 1471 1536 1544 1560 1569 1607 1643 1663 1629 1619 1603 1572 1536 1507 1467 1419 1464 1518 1548 1552 1522 1569 1604 1625
				1645 1661 1600 1558 1589 1552 1542 1491 1455 1500 1516 1549 1592 1617 1629 1640 1605 1639 1586 1548 1528 1498 1480 1428 1448 1493 1521 1549 1544 1572 1578 1588
				1651 1650 1600 1590 1609 1569 1536 1484 1474 1534 1568 1581 1596 1610 1638 1655 1626 1638 1588 1579 1557 1514 1487 1425 1465 1529 1556 1590 1544 1561 1601 1624
				1648 1645 1630 1572 1581 1562 1528 1500 1458 1515 1530 1552 1585 1635 1644 1639 1619 1612 1610 1561 1529 1506 1482 1440 1459 1501 1526 1557 1538 1588 1602 1590
				1675 1655 1629 1572 1617 1583 1545 1495 1467 1535 1565 1605 1617 1635 1635 1649 1649 1637 1614 1558 1560 1529 1499 1444 1463 1522 1563 1591 1579 1581 1588 1613
				1640 1652 1623 1600 1600 1558 1542 1488 1482 1518 1546 1563 1585 1621 1663 1659 1615 1627 1593 1579 1544 1512 1494 1437 1489 1516 1543 1560 1549 1573 1620 1614
				1686 1679 1635 1601 1601 1594 1563 1503 1486 1528 1566 1604 1643 1654 1661 1648 1661 1662 1619 1590 1544 1539 1520 1456 1477 1522 1563 1601 1579 1618 1607 1611
				1649 1645 1632 1599 1632 1573 1536 1497 1522 1543 1551 1581 1599 1622 1647 1674 1627 1626 1610 1569 1566 1522 1491 1446 1510 1546 1557 1576 1551 1579 1601 1634
				1665 1687 1657 1608 1630 1576 1572 1518 1509 1547 1561 1601 1642 1681 1679 1673 1640 1673 1639 1590 1567 1523 1519 1468 1505 1536 1564 1598 1592 1617 1645 1623
				1688 1653 1627 1603 1625 1603 1553 1495 1489 1584 1576 1584 1617 1631 1647 1658 1653 1634 1608 1581 1550 1544 1507 1451 1486 1569 1588 1594 1567 1584 1610 1615
				1671 1666 1665 1625 1636 1605 1555 1527 1519 1570 1579 1596 1635 1675 1705 1690 1640 1645 1652 1610 1574 1544 1502 1476 1525 1562 1572 1597 1584 1620 1642 1665
				1668 1689 1635 1597 1632 1602 1581 1507 1492 1549 1620 1613 1620 1648 1657 1658 1648 1657 1622 1585 1567 1528 1522 1467 1493 1541 1612 1625 1581 1597 1608 1625
				1662 1675 1653 1634 1660 1615 1587 1512 1506 1579 1608 1616 1632 1665 1702 1718 1652 1651 1630 1622 1593 1552 1530 1467 1496 1580 1605 1608 1585 1615 1650 1662
				1669 1672 1674 1608 1629 1607 1582 1536 1483 1556 1582 1656 1650 1651 1677 1668 1650 1659 1647 1595 1567 1546 1514 1478 1469 1555 1582 1647 1611 1609 1623 1626
				1681 1664 1659 1629 1668 1634 1597 1540 1505 1542 1614 1646 1653 1663 1692 1715 1676 1662 1644 1610 1606 1570 1538 1492 1515 1534 1626 1639 1595 1616 1644 1671
				1677 1672 1656 1647 1639 1603 1586 1537 1500 1521 1587 1618 1698 1679 1675 1689 1660 1651 1648 1621 1577 1545 1528 1472 1486 1504 1592 1616 1635 1639 1638 1638
				1710 1681 1646 1632 1659 1639 1612 1549 1521 1542 1572 1651 1684 1679 1687 1702 1697 1681 1648 1615 1590 1579 1551 1497 1515 1553 1566 1658 1625 1621 1638 1658
				1684 1676 1657 1626 1678 1614 1586 1537 1499 1536 1550 1621 1651 1721 1704 1686 1669 1667 1644 1621 1602 1552 1533 1485 1495 1521 1538 1626 1600 1659 1666 1654
				1717 1713 1665 1620 1668 1636 1620 1564 1506 1554 1572 1605 1684 1708 1704 1699 1704 1702 1671 1626 1599 1570 1566 1512 1521 1551 1584 1600 1641 1647 1650 1650
				1683 1689 1661 1632 1664 1656 1597 1539 1522 1532 1567 1582 1656 1675 1749 1715 1672 1679 1657 1624 1605 1579 1540 1486 1513 1528 1554 1574 1608 1624 1687 1677
				1730 1717 1697 1642 1656 1643 1619 1572 1519 1541 1587 1607 1641 1711 1733 1714 1694 1707 1692 1650 1609 1578 1557 1519 1516 1552 1581 1623 1583 1663 1680 1654
				1704 1682 1672 1637 1666 1638 1634 1550 1513 1556 1563 1601 1618 1681 1701 1762 1678 1677 1665 1637 1603 1585 1566 1500 1507 1552 1564 1588 1556 1629 1653 1690
				1687 1725 1699 1674 1674 1628 1619 1570 1547 1551 1574 1624 1644 1689 1739 1746 1685 1702 1696 1671 1631 1584 1559 1516 1529 1548 1591 1622 1603 1630 1695 1681
				1704 1703 1665 1648 1672 1637 1618 1585 1529 1545 1588 1597 1638 1663 1707 1711 1705 1681 1671 1646 1614 1579 1569 1524 1527 1542 1589 1600 1570 1599 1658 1650
				1700 1686 1704 1674 1708 1645 1606 1571 1547 1579 1585 1606 1659 1689 1718 1747 1682 1690 1684 1674 1650 1605 1568 1519 1548 1566 1579 1628 1603 1649 1660 1691
				1702 1703 1689 1647 1685 1647 1620 1572 1525 1557 1579 1618 1635 1683 1695 1717 1696 1710 1675 1650 1626 1594 1567 1533 1523 1557 1573 1623 1581 1620 1632 1656
				(-511) (-511) (-511)>;

			PS_Config_Lmt_FW_Rawdata_P = <
				1106 1113 1117 1120 1127 1113 1122 1117 1115 1115 1100 1111 1121 1115 1113 1106 1122 1113 1115 1108 1118 1122 1111 1117 1115 1115 1114 1121 1114 1113 1107 1122
				1117 1121 1121 1125 1113 1128 1124 1115 1113 1115 1114 1115 1107 1106 1117 1111 1122 1110 1114 1115 1124 1128 1114 1124 1114 1115 1124 1124 1115 1114 1121 1117
				1106 1113 1122 1110 1118 1115 1124 1106 1115 1124 1121 1122 1117 1111 1118 1118 1120 1117 1114 1114 1118 1108 1111 1127 1110 1111 1106 1118 1114 1120 1124 1111
				1118 1121 1118 1122 1125 1115 1132 1108 1129 1111 1113 1120 1124 1120 1114 1125 1125 1124 1111 1118 1114 1122 1122 1125 1114 1113 1107 1131 1118 1127 1118 1121
				1108 1127 1115 1118 1108 1120 1115 1128 1128 1124 1124 1122 1129 1117 1113 1132 1127 1125 1122 1113 1117 1122 1114 1118 1129 1106 1108 1114 1113 1117 1127 1111
				1110 1108 1122 1120 1124 1124 1113 1136 1127 1122 1113 1111 1113 1117 1124 1122 1120 1120 1118 1110 1124 1124 1117 1122 1108 1120 1115 1097 1115 1118 1132 1127
				1128 1122 1129 1115 1120 1108 1110 1118 1122 1120 1128 1118 1124 1135 1107 1127 1127 1124 1124 1122 1114 1121 1127 1111 1124 1127 1103 1117 1120 1113 1120 1127
				1117 1125 1111 1118 1121 1124 1117 1117 1118 1134 1129 1114 1111 1117 1115 1129 1122 1117 1121 1128 1117 1127 1114 1108 1125 1122 1121 1113 1103 1115 1115 1097
				1127 1120 1127 1124 1114 1120 1110 1114 1125 1128 1125 1120 1117 1114 1136 1106 1121 1120 1125 1127 1122 1113 1125 1125 1124 1113 1115 1111 1118 1127 1114 1114
				1118 1124 1128 1113 1120 1120 1120 1117 1100 1110 1134 1128 1114 1111 1125 1107 1127 1124 1122 1121 1125 1113 1124 1122 1127 1118 1121 1117 1107 1107 1118 1113
				1127 1118 1117 1125 1125 1110 1121 1114 1118 1104 1132 1117 1124 1115 1115 1127 1125 1118 1121 1121 1125 1124 1120 1122 1108 1107 1104 1111 1111 1120 1128 1120
				1124 1132 1136 1127 1113 1118 1118 1111 1113 1114 1108 1135 1125 1129 1114 1124 1107 1124 1129 1121 1122 1121 1113 1120 1124 1118 1120 1124 1121 1111 1113 1120
				1108 1125 1118 1115 1122 1127 1113 1115 1117 1125 1115 1136 1115 1122 1108 1121 1120 1120 1115 1120 1124 1120 1127 1113 1117 1114 1108 1106 1104 1115 1124 1106
				1114 1115 1128 1127 1132 1114 1118 1117 1122 1122 1113 1113 1132 1115 1113 1115 1125 1106 1122 1125 1117 1122 1125 1115 1124 1132 1117 1111 1129 1124 1114 1128
				1121 1132 1122 1118 1117 1122 1124 1111 1115 1117 1125 1113 1141 1106 1125 1114 1114 1120 1124 1127 1118 1124 1125 1125 1118 1127 1115 1111 1108 1101 1118 1117
				1122 1114 1118 1129 1124 1129 1104 1122 1117 1120 1121 1113 1115 1135 1115 1114 1120 1122 1107 1121 1117 1117 1131 1124 1115 1115 1122 1114 1117 1131 1117 1129
				1118 1114 1131 1120 1118 1117 1125 1131 1121 1111 1115 1135 1107 1120 1099 1114 1108 1115 1117 1127 1128 1117 1128 1125 1121 1124 1129 1118 1108 1114 1110 1125
				1111 1110 1118 1121 1122 1124 1124 1108 1118 1114 1117 1125 1122 1121 1135 1110 1118 1121 1122 1111 1124 1118 1122 1129 1122 1115 1120 1118 1101 1118 1128 1110
				1134 1118 1113 1128 1121 1117 1122 1127 1113 1107 1134 1118 1128 1106 1115 1106 1122 1110 1115 1117 1125 1125 1111 1129 1114 1115 1131 1125 1115 1110 1114 1122
				1127 1106 1118 1120 1120 1125 1113 1128 1111 1114 1110 1117 1125 1120 1121 1101 1127 1122 1117 1122 1108 1118 1129 1121 1118 1122 1120 1108 1118 1113 1117 1108
				1115 1111 1114 1113 1132 1122 1124 1118 1124 1117 1110 1110 1118 1129 1110 1114 1120 1125 1113 1117 1120 1121 1110 1117 1110 1117 1113 1128 1128 1117 1107 1127
				1117 1115 1106 1121 1124 1121 1135 1127 1127 1114 1114 1114 1120 1127 1120 1124 1122 1127 1121 1120 1121 1110 1129 1129 1127 1115 1122 1115 1104 1117 1104 1111
				1118 1124 1110 1113 1110 1131 1128 1118 1106 1110 1118 1108 1113 1117 1127 1120 1122 1120 1125 1114 1118 1122 1122 1111 1117 1113 1117 1115 1128 1131 1115 1110
				1124 1110 1115 1120 1117 1120 1124 1132 1131 1122 1111 1111 1114 1118 1129 1122 1120 1127 1125 1120 1115 1122 1118 1131 1131 1124 1108 1120 1114 1107 1108 1122
				1129 1128 1127 1108 1114 1120 1132 1120 1129 1101 1122 1114 1110 1111 1120 1125 1120 1125 1121 1125 1115 1120 1131 1125 1118 1122 1117 1118 1120 1127 1134 1120
				1131 1125 1107 1117 1120 1124 1118 1124 1120 1111 1124 1114 1111 1117 1117 1129 1117 1114 1122 1122 1121 1120 1122 1113 1110 1107 1134 1113 1117 1114 1108 1114
				1118 1122 1125 1122 1108 1113 1113 1127 1114 1125 1113 1122 1117 1106 1110 1111 1110 1121 1122 1124 1125 1110 1113 1125 1111 1120 1118 1113 1115 1121 1129 1104
				1108 1121 1124 1108 1115 1125 1120 1117 1118 1120 1121 1125 1115 1114 1113 1118 1111 1113 1114 1127 1134 1120 1114 1118 1111 1107 1108 1124 1113 1117 1115 1118
				1113 1106 1120 1124 1122 1106 1115 1114 1120 1118 1129 1113 1122 1115 1110 1110 1120 1113 1118 1124 1122 1127 1110 1117 1115 1113 1120 1120 1117 1117 1108 1106
				1117 1128 1117 1120 1110 1114 1120 1125 1125 1115 1122 1117 1125 1113 1111 1110 1124 1113 1115 1114 1122 1131 1124 1118 1114 1121 1103 1107 1132 1111 1115 1118
				1127 1124 1110 1117 1125 1118 1107 1111 1118 1131 1113 1127 1111 1129 1114 1106 1117 1120 1113 1122 1122 1120 1128 1110 1121 1113 1114 1122 1120 1110 1121 1121
				1118 1120 1124 1117 1122 1113 1120 1125 1120 1125 1121 1121 1115 1122 1111 1110 1120 1120 1111 1115 1115 1122 1108 1122 1124 1125 1114 1106 1103 1124 1108 1115
				1118 1113 1122 1111 1115 1127 1117 1097 1129 1121 1121 1114 1125 1120 1129 1113 1127 1113 1122 1114 1124 1124 1120 1124 1111 1106 1113 1114 1122 1120 1113 1118
				1111 1114 1115 1117 1115 1118 1113 1111 1113 1118 1118 1121 1114 1113 1128 1113 1117 1118 1124 1121 1118 1118 1128 1113 1114 1108 1120 1118 1101 1107 1131 1120
				1111 1117 1106 1121 1108 1118 1125 1118 1120 1107 1115 1120 1114 1127 1124 1129 1113 1122 1114 1124 1118 1125 1125 1129 1118 1115 1118 1117 1115 1118 1118 1121
				1120 1124 1115 1117 1118 1115 1124 1124 1113 1120 1115 1124 1118 1117 1114 1128 1121 1127 1117 1118 1125 1117 1111 1122 1114 1120 1107 1117 1115 1104 1107 1107
				1113 1127 1117 1104 1121 1111 1117 1120 1127 1122 1121 1115 1120 1113 1127 1118 1120 1113 1124 1110 1122 1117 1127 1122 1117 1117 1114 1124 1114 1115 1121 1124
				1128 1122 1125 1114 1118 1122 1115 1117 1113 1110 1114 1120 1121 1124 1114 1110 1114 1118 1125 1117 1117 1115 1118 1115 1115 1114 1117 1113 1117 1117 1104 1121
				1134 1120 1129 1118 1104 1115 1111 1114 1115 1114 1120 1118 1113 1114 1115 1124 1100 1114 1111 1121 1114 1121 1113 1129 1124 1108 1121 1114 1121 1114 1114 1118
				1136 1121 1125 1124 1114 1121 1128 1120 1124 1115 1114 1115 1120 1128 1129 1118 1118 1110 1121 1120 1118 1121 1113 1122 1125 1115 1111 1120 1117 1117 1115 1121
				1127 1117 1114 1129 1120 1101 1118 1113 1127 1114 1122 1121 1120 1110 1111 1114 1121 1111 1115 1111 1122 1113 1121 1108 1110 1118 1118 1122 1110 1122 1115 1125
				1117 1115 1118 1125 1122 1114 1117 1129 1120 1117 1117 1111 1113 1118 1124 1122 1111 1120 1111 1118 1125 1114 1122 1111 1131 1129 1118 1104 1118 1120 1115 1117
				1108 1100 1113 1117 1131 1122 1101 1115 1110 1118 1118 1120 1122 1125 1107 1124 1121 1118 1111 1113 1111 1120 1115 1115 1125 1111 1121 1120 1121 1108 1121 1115
				1111 1104 1114 1117 1125 1118 1114 1121 1117 1113 1118 1124 1111 1115 1120 1115 1121 1111 1120 1110 1122 1127 1117 1122 1132 1132 1131 1118 1106 1117 1115 1118
				1113 1125 1106 1110 1115 1121 1122 1106 1111 1114 1118 1120 1122 1125 1121 1115 1121 1121 1115 1113 1111 1111 1121 1115 1125 1128 1113 1121 1117 1121 1111 1111
				1118 1122 1120 1103 1111 1117 1122 1110 1120 1113 1113 1114 1115 1114 1113 1124 1117 1118 1111 1122 1108 1122 1124 1120 1115 1131 1134 1124 1111 1113 1118 1110
				1115 1118 1124 1131 1110 1114 1124 1118 1128 1120 1115 1118 1120 1127 1124 1110 1131 1120 1121 1118 1107 1114 1111 1125 1111 1117 1131 1117 1120 1113 1125 1118
				1125 1121 1122 1127 1111 1111 1124 1117 1125 1122 1127 1127 1125 1117 1129 1118 1124 1118 1115 1108 1114 1108 1124 1111 1114 1107 1132 1136 1124 1111 1117 1108
				3840 3840 3840>;

			PS_Config_Lmt_FW_Rawdata_N = <
				474 477 478 480 483 477 481 478 478 478 471 476 480 478 477 474 481 477 478 475 479 481 476 478 478 478 477 480 477 477 474 481
				478 480 480 482 477 483 481 478 477 478 477 478 474 474 478 476 481 475 477 478 481 483 477 481 477 478 481 481 478 477 480 478
				474 477 481 475 479 478 481 474 478 481 480 481 478 476 479 479 480 478 477 477 479 475 476 483 475 476 474 479 477 480 481 476
				479 480 479 481 482 478 485 475 484 476 477 480 481 480 477 482 482 481 476 479 477 481 481 482 477 477 474 484 479 483 479 480
				475 483 478 479 475 480 478 483 483 481 481 481 484 478 477 485 483 482 481 477 478 481 477 479 484 474 475 477 477 478 483 476
				475 475 481 480 481 481 477 487 483 481 477 476 477 478 481 481 480 480 479 475 481 481 478 481 475 480 478 470 478 479 485 483
				483 481 484 478 480 475 475 479 481 480 483 479 481 486 474 483 483 481 481 481 477 480 483 476 481 483 472 478 480 477 480 483
				478 482 476 479 480 481 478 478 479 486 484 477 476 478 478 484 481 478 480 483 478 483 477 475 482 481 480 477 472 478 478 470
				483 480 483 481 477 480 475 477 482 483 482 480 478 477 487 474 480 480 482 483 481 477 482 482 481 477 478 476 479 483 477 477
				479 481 483 477 480 480 480 478 471 475 486 483 477 476 482 474 483 481 481 480 482 477 481 481 483 479 480 478 474 474 479 477
				483 479 478 482 482 475 480 477 479 473 485 478 481 478 478 483 482 479 480 480 482 481 480 481 475 474 473 476 476 480 483 480
				481 485 487 483 477 479 479 476 477 477 475 486 482 484 477 481 474 481 484 480 481 480 477 480 481 479 480 481 480 476 477 480
				475 482 479 478 481 483 477 478 478 482 478 487 478 481 475 480 480 480 478 480 481 480 483 477 478 477 475 474 473 478 481 474
				477 478 483 483 485 477 479 478 481 481 477 477 485 478 477 478 482 474 481 482 478 481 482 478 481 485 478 476 484 481 477 483
				480 485 481 479 478 481 481 476 478 478 482 477 489 474 482 477 477 480 481 483 479 481 482 482 479 483 478 476 475 472 479 478
				481 477 479 484 481 484 473 481 478 480 480 477 478 486 478 477 480 481 474 480 478 478 484 481 478 478 481 477 478 484 478 484
				479 477 484 480 479 478 482 484 480 476 478 486 474 480 471 477 475 478 478 483 483 478 483 482 480 481 484 479 475 477 475 482
				476 475 479 480 481 481 481 475 479 477 478 482 481 480 486 475 479 480 481 476 481 479 481 484 481 478 480 479 472 479 483 475
				486 479 477 483 480 478 481 483 477 474 486 479 483 474 478 474 481 475 478 478 482 482 476 484 477 478 484 482 478 475 477 481
				483 474 479 480 480 482 477 483 476 477 475 478 482 480 480 472 483 481 478 481 475 479 484 480 479 481 480 475 479 477 478 475
				478 476 477 477 485 481 481 479 481 478 475 475 479 484 475 477 480 482 477 478 480 480 475 478 475 478 477 483 483 478 474 483
				478 478 474 480 481 480 486 483 483 477 477 477 480 483 480 481 481 483 480 480 480 475 484 484 483 478 481 478 473 478 473 476
				479 481 475 477 475 484 483 479 474 475 479 475 477 478 483 480 481 480 482 477 479 481 481 476 478 477 478 478 483 484 478 475
				481 475 478 480 478 480 481 485 484 481 476 476 477 479 484 481 480 483 482 480 478 481 479 484 484 481 475 480 477 474 475 481
				484 483 483 475 477 480 485 480 484 472 481 477 475 476 480 482 480 482 480 482 478 480 484 482 479 481 478 479 480 483 486 480
				484 482 474 478 480 481 479 481 480 476 481 477 476 478 478 484 478 477 481 481 480 480 481 477 475 474 486 477 478 477 475 477
				479 481 482 481 475 477 477 483 477 482 477 481 478 474 475 476 475 480 481 481 482 475 477 482 476 480 479 477 478 480 484 473
				475 480 481 475 478 482 480 478 479 480 480 482 478 477 477 479 476 477 477 483 486 480 477 479 476 474 475 481 477 478 478 479
				477 474 480 481 481 474 478 477 480 479 484 477 481 478 475 475 480 477 479 481 481 483 475 478 478 477 480 480 478 478 475 474
				478 483 478 480 475 477 480 482 482 478 481 478 482 477 476 475 481 477 478 477 481 484 481 479 477 480 472 474 485 476 478 479
				483 481 475 478 482 479 474 476 479 484 477 483 476 484 477 474 478 480 477 481 481 480 483 475 480 477 477 481 480 475 480 480
				479 480 481 478 481 477 480 482 480 482 480 480 478 481 476 475 480 480 476 478 478 481 475 481 481 482 477 474 472 481 475 478
				479 477 481 476 478 483 478 470 484 480 480 477 482 480 484 477 483 477 481 477 481 481 480 481 476 474 477 477 481 480 477 479
				476 477 478 478 478 479 477 476 477 479 479 480 477 477 483 477 478 479 481 480 479 479 483 477 477 475 480 479 472 474 484 480
				476 478 474 480 475 479 482 479 480 474 478 480 477 483 481 484 477 481 477 481 479 482 482 484 479 478 479 478 478 479 479 480
				480 481 478 478 479 478 481 481 477 480 478 481 479 478 477 483 480 483 478 479 482 478 476 481 477 480 474 478 478 473 474 474
				477 483 478 473 480 476 478 480 483 481 480 478 480 477 483 479 480 477 481 475 481 478 483 481 478 478 477 481 477 478 480 481
				483 481 482 477 479 481 478 478 477 475 477 480 480 481 477 475 477 479 482 478 478 478 479 478 478 477 478 477 478 478 473 480
				486 480 484 479 473 478 476 477 478 477 480 479 477 477 478 481 471 477 476 480 477 480 477 484 481 475 480 477 480 477 477 479
				487 480 482 481 477 480 483 480 481 478 477 478 480 483 484 479 479 475 480 480 479 480 477 481 482 478 476 480 478 478 478 480
				483 478 477 484 480 472 479 477 483 477 481 480 480 475 476 477 480 476 478 476 481 477 480 475 475 479 479 481 475 481 478 482
				478 478 479 482 481 477 478 484 480 478 478 476 477 479 481 481 476 480 476 479 482 477 481 476 484 484 479 473 479 480 478 478
				475 471 477 478 484 481 472 478 475 479 479 480 481 482 474 481 480 479 476 477 476 480 478 478 482 476 480 480 480 475 480 478
				476 473 477 478 482 479 477 480 478 477 479 481 476 478 480 478 480 476 480 475 481 483 478 481 485 485 484 479 474 478 478 479
				477 482 474 475 478 480 481 474 476 477 479 480 481 482 480 478 480 480 478 477 476 476 480 478 482 483 477 480 478 480 476 476
				479 481 480 472 476 478 481 475 480 477 477 477 478 477 477 481 478 479 476 481 475 481 481 480 478 484 486 481 476 477 479 475
				478 479 481 484 475 477 481 479 483 480 478 479 480 483 481 475 484 480 480 479 474 477 476 482 476 478 484 478 480 477 482 479
				482 480 481 483 476 476 481 478 482 481 483 483 482 478 484 479 481 479 478 475 477 475 481 476 477 474 485 487 481 476 478 475
				240 240 240>;

			PS_Config_Lmt_FW_CC_P = <
				64 57 62 62 64 64 63 63 63 63 63 63 63 63 63 66 64 57 62 62 63 63 63 63 63 63 63 63 63 63 63 66
				63 57 60 62 62 62 62 62 63 60 60 62 62 62 63 62 62 57 60 62 62 62 63 62 63 62 62 62 62 62 63 62
				63 63 57 62 62 63 63 63 63 62 63 62 62 62 62 62 62 63 56 62 62 63 63 62 62 62 63 62 62 62 62 63
				63 62 57 60 62 62 62 63 62 63 60 60 62 62 62 63 62 62 57 60 63 62 62 63 62 63 62 62 62 62 62 63
				63 62 63 57 62 62 63 63 62 63 62 63 62 62 62 62 63 62 62 56 62 62 63 63 62 62 62 63 62 62 62 63
				62 63 62 57 62 63 62 62 63 62 63 62 62 62 62 62 62 62 62 57 60 63 62 62 62 62 63 62 62 62 62 63
				62 63 62 63 57 62 62 63 62 62 62 62 63 62 63 62 62 63 62 62 56 62 62 63 62 62 62 62 63 62 62 62
				63 62 63 62 57 62 63 62 62 63 62 63 62 62 62 62 63 62 62 62 57 60 63 62 62 63 62 63 62 62 62 63
				62 62 63 62 63 57 62 62 62 62 62 63 62 63 63 63 62 62 63 62 63 56 62 62 62 62 62 62 62 63 62 63
				63 63 62 63 62 57 62 63 62 62 63 62 63 62 62 63 63 63 62 62 62 57 60 63 62 62 63 62 63 62 62 63
				62 62 62 63 62 63 57 62 63 62 62 62 63 63 63 63 60 62 62 63 62 62 56 62 63 62 62 62 62 62 63 63
				63 63 63 62 63 62 57 62 62 62 62 63 62 63 62 62 63 63 63 62 62 62 57 62 62 62 62 63 62 63 62 62
				63 62 62 62 63 62 63 57 62 63 62 62 62 63 63 63 63 62 62 62 63 62 63 56 62 63 62 62 63 62 63 63
				63 63 63 63 62 62 62 57 63 62 62 62 63 62 63 62 62 63 63 63 62 62 62 57 63 62 62 62 63 62 63 62
				63 63 62 62 62 63 62 63 62 62 63 62 62 62 63 63 62 63 60 62 62 63 62 63 63 62 63 62 62 63 62 63
				63 62 63 63 63 62 63 62 63 63 62 63 62 63 62 63 63 62 63 63 63 62 62 62 63 64 62 62 62 63 62 63
				63 63 63 62 62 62 63 62 63 63 62 63 62 62 62 63 63 62 63 60 62 62 63 62 63 63 62 63 63 62 63 63
				63 63 62 63 63 63 62 63 62 63 63 62 63 62 63 63 62 63 62 63 63 63 62 62 62 63 63 62 63 62 63 63
				63 63 63 63 62 62 62 63 63 63 62 62 63 62 63 62 63 63 62 63 60 62 62 63 63 63 63 63 63 63 62 63
				63 63 63 62 63 63 63 62 62 62 63 63 62 63 62 63 63 62 63 62 63 63 63 62 63 63 63 64 62 62 63 63
				63 63 63 63 63 62 62 62 63 63 63 62 62 63 62 63 62 63 63 62 63 62 62 62 63 63 63 63 63 63 63 63
				63 62 63 63 62 63 63 63 62 63 62 63 63 62 63 62 63 63 62 63 62 63 63 63 62 63 63 63 64 62 62 63
				63 62 63 63 63 63 62 62 64 63 63 63 63 63 63 63 62 62 63 63 62 63 62 62 64 63 63 63 63 63 63 64
				64 63 62 62 63 62 63 63 62 62 63 62 63 63 62 63 63 63 63 62 63 62 63 63 62 63 63 63 63 64 63 63
				64 62 62 63 63 62 63 62 63 64 63 63 63 63 63 63 63 62 62 63 63 62 63 62 63 64 63 63 63 63 63 64
				63 63 63 62 62 63 62 63 63 63 62 63 62 63 63 62 62 62 63 63 62 63 62 63 63 63 62 63 63 63 64 63
				63 64 62 62 63 63 63 63 63 63 64 63 63 63 63 63 63 63 62 62 63 63 62 63 63 63 64 63 63 63 63 63
				63 62 62 63 62 62 63 62 63 63 62 62 63 62 63 63 63 62 62 63 63 62 63 62 63 64 63 63 63 63 63 64
				64 63 64 62 62 63 63 62 63 63 63 64 63 63 63 63 63 63 63 62 62 63 63 62 63 63 63 64 63 63 63 63
				63 63 62 62 63 62 62 63 63 63 63 62 62 63 62 63 62 63 62 62 63 63 62 63 64 63 64 63 62 63 63 63
				63 63 63 64 62 62 63 63 63 63 63 63 64 63 63 63 63 63 63 63 62 62 63 63 63 63 63 63 64 63 63 63
				64 62 63 62 62 63 62 62 62 63 63 63 62 62 63 62 63 62 63 62 62 63 63 62 62 64 63 64 63 62 63 63
				63 63 63 63 64 62 62 63 63 63 63 63 63 63 63 63 63 63 63 63 63 62 62 63 63 63 63 63 63 64 63 64
				64 63 62 63 62 62 63 62 60 62 63 63 63 62 62 63 63 63 62 63 62 62 63 63 62 63 64 63 63 63 62 63
				63 63 63 63 63 64 62 62 57 63 63 63 63 63 63 63 62 63 63 63 63 63 62 62 57 63 63 63 63 63 64 63
				63 63 63 62 63 62 62 63 57 60 62 63 63 63 62 62 63 63 63 62 63 62 62 63 57 62 63 64 63 63 63 63
				64 62 63 63 63 63 64 62 63 57 63 63 63 63 63 64 63 62 63 63 63 63 63 62 63 57 63 63 63 63 63 64
				63 63 63 63 62 63 62 62 62 57 60 62 63 63 63 62 62 63 63 63 62 63 62 62 62 57 62 62 64 63 63 63
				63 63 62 63 63 63 63 64 62 63 57 63 63 63 63 63 63 63 62 63 63 63 63 63 62 63 57 63 63 63 63 63
				63 63 63 63 63 62 63 62 63 62 57 60 62 63 63 63 63 62 63 63 63 62 63 63 63 62 57 62 62 64 63 64
				64 63 63 62 63 63 63 63 62 62 63 57 63 63 63 63 63 63 63 62 63 63 63 63 63 62 63 57 63 63 63 63
				63 63 63 63 63 63 62 63 62 63 62 57 60 62 63 63 62 63 62 63 63 63 62 63 62 63 62 57 62 62 64 64
				64 64 63 63 62 63 63 63 62 62 62 63 57 63 63 63 63 63 63 63 62 63 63 63 62 63 62 63 57 63 63 63
				63 62 63 63 63 63 63 62 62 62 63 62 57 60 62 63 62 62 63 62 63 63 63 62 62 62 63 62 57 62 62 64
				63 64 63 63 63 62 63 63 62 62 62 62 63 57 63 63 62 63 63 63 63 62 63 63 63 62 63 62 63 57 63 64
				64 63 62 63 63 63 63 63 62 62 62 63 62 57 60 63 64 62 62 63 62 63 63 63 62 62 62 63 62 57 60 64
				63 62 63 63 63 63 62 63 62 62 62 62 62 63 57 63 62 62 63 63 63 63 62 63 62 63 62 63 62 63 57 63
				62 63 63 62 63 63 63 63 62 62 62 63 63 62 57 63 63 63 63 62 63 63 63 63 62 62 62 62 63 62 57 62
				314 314 314>;

			PS_Config_Lmt_FW_CC_N = <
				29 26 27 27 29 29 28 28 28 28 28 28 28 28 28 29 29 26 27 27 28 28 28 28 28 28 28 28 28 28 28 29
				28 26 27 27 27 27 27 27 28 27 27 27 27 27 28 27 27 26 27 27 27 27 28 27 28 27 27 27 27 27 28 27
				28 28 26 27 27 28 28 28 28 27 28 27 27 27 27 27 27 28 25 27 27 28 28 27 27 27 28 27 27 27 27 28
				28 27 26 27 27 27 27 28 27 28 27 27 27 27 27 28 27 27 26 27 28 27 27 28 27 28 27 27 27 27 27 28
				28 27 28 26 27 27 28 28 27 28 27 28 27 27 27 27 28 27 27 25 27 27 28 28 27 27 27 28 27 27 27 28
				27 28 27 26 27 28 27 27 28 27 28 27 27 27 27 27 27 27 27 26 27 28 27 27 27 27 28 27 27 27 27 28
				27 28 27 28 26 27 27 28 27 27 27 27 28 27 28 27 27 28 27 27 25 27 27 28 27 27 27 27 28 27 27 27
				28 27 28 27 26 27 28 27 27 28 27 28 27 27 27 27 28 27 27 27 26 27 28 27 27 28 27 28 27 27 27 28
				27 27 28 27 28 26 27 27 27 27 27 28 27 28 28 28 27 27 28 27 28 25 27 27 27 27 27 27 27 28 27 28
				28 28 27 28 27 26 27 28 27 27 28 27 28 27 27 28 28 28 27 27 27 26 27 28 27 27 28 27 28 27 27 28
				27 27 27 28 27 28 26 27 28 27 27 27 28 28 28 28 27 27 27 28 27 27 25 27 28 27 27 27 27 27 28 28
				28 28 28 27 28 27 26 27 27 27 27 28 27 28 27 27 28 28 28 27 27 27 26 27 27 27 27 28 27 28 27 27
				28 27 27 27 28 27 28 26 27 28 27 27 27 28 28 28 28 27 27 27 28 27 28 25 27 28 27 27 28 27 28 28
				28 28 28 28 27 27 27 26 28 27 27 27 28 27 28 27 27 28 28 28 27 27 27 26 28 27 27 27 28 27 28 27
				28 28 27 27 27 28 27 28 27 27 28 27 27 27 28 28 27 28 27 27 27 28 27 28 28 27 28 27 27 28 27 28
				28 27 28 28 28 27 28 27 28 28 27 28 27 28 27 28 28 27 28 28 28 27 27 27 28 29 27 27 27 28 27 28
				28 28 28 27 27 27 28 27 28 28 27 28 27 27 27 28 28 27 28 27 27 27 28 27 28 28 27 28 28 27 28 28
				28 28 27 28 28 28 27 28 27 28 28 27 28 27 28 28 27 28 27 28 28 28 27 27 27 28 28 27 28 27 28 28
				28 28 28 28 27 27 27 28 28 28 27 27 28 27 28 27 28 28 27 28 27 27 27 28 28 28 28 28 28 28 27 28
				28 28 28 27 28 28 28 27 27 27 28 28 27 28 27 28 28 27 28 27 28 28 28 27 28 28 28 29 27 27 28 28
				28 28 28 28 28 27 27 27 28 28 28 27 27 28 27 28 27 28 28 27 28 27 27 27 28 28 28 28 28 28 28 28
				28 27 28 28 27 28 28 28 27 28 27 28 28 27 28 27 28 28 27 28 27 28 28 28 27 28 28 28 29 27 27 28
				28 27 28 28 28 28 27 27 29 28 28 28 28 28 28 28 27 27 28 28 27 28 27 27 29 28 28 28 28 28 28 29
				29 28 27 27 28 27 28 28 27 27 28 27 28 28 27 28 28 28 28 27 28 27 28 28 27 28 28 28 28 29 28 28
				29 27 27 28 28 27 28 27 28 29 28 28 28 28 28 28 28 27 27 28 28 27 28 27 28 29 28 28 28 28 28 29
				28 28 28 27 27 28 27 28 28 28 27 28 27 28 28 27 27 27 28 28 27 28 27 28 28 28 27 28 28 28 29 28
				28 29 27 27 28 28 28 28 28 28 29 28 28 28 28 28 28 28 27 27 28 28 27 28 28 28 29 28 28 28 28 28
				28 27 27 28 27 27 28 27 28 28 27 27 28 27 28 28 28 27 27 28 28 27 28 27 28 29 28 28 28 28 28 29
				29 28 29 27 27 28 28 27 28 28 28 29 28 28 28 28 28 28 28 27 27 28 28 27 28 28 28 29 28 28 28 28
				28 28 27 27 28 27 27 28 28 28 28 27 27 28 27 28 27 28 27 27 28 28 27 28 29 28 29 28 27 28 28 28
				28 28 28 29 27 27 28 28 28 28 28 28 29 28 28 28 28 28 28 28 27 27 28 28 28 28 28 28 29 28 28 28
				29 27 28 27 27 28 27 27 27 28 28 28 27 27 28 27 28 27 28 27 27 28 28 27 27 29 28 29 28 27 28 28
				28 28 28 28 29 27 27 28 28 28 28 28 28 28 28 28 28 28 28 28 28 27 27 28 28 28 28 28 28 29 28 29
				29 28 27 28 27 27 28 27 27 27 28 28 28 27 27 28 28 28 27 28 27 27 28 28 27 28 29 28 28 28 27 28
				28 28 28 28 28 29 27 27 26 28 28 28 28 28 28 28 27 28 28 28 28 28 27 27 26 28 28 28 28 28 29 28
				28 28 28 27 28 27 27 28 26 27 27 28 28 28 27 27 28 28 28 27 28 27 27 28 26 27 28 29 28 28 28 28
				29 27 28 28 28 28 29 27 28 26 28 28 28 28 28 29 28 27 28 28 28 28 28 27 28 26 28 28 28 28 28 29
				28 28 28 28 27 28 27 27 27 26 27 27 28 28 28 27 27 28 28 28 27 28 27 27 27 26 27 27 29 28 28 28
				28 28 27 28 28 28 28 29 27 28 26 28 28 28 28 28 28 28 27 28 28 28 28 28 27 28 26 28 28 28 28 28
				28 28 28 28 28 27 28 27 28 27 26 27 27 28 28 28 28 27 28 28 28 27 28 28 28 27 26 27 27 29 28 29
				29 28 28 27 28 28 28 28 27 27 28 26 28 28 28 28 28 28 28 27 28 28 28 28 28 27 28 26 28 28 28 28
				28 28 28 28 28 28 27 28 27 28 27 26 27 27 28 28 27 28 27 28 28 28 27 28 27 28 27 26 27 27 29 29
				29 29 28 28 27 28 28 28 27 27 27 28 26 28 28 28 28 28 28 28 27 28 28 28 27 28 27 28 26 28 28 28
				28 27 28 28 28 28 28 27 27 27 28 27 26 27 27 28 27 27 28 27 28 28 28 27 27 27 28 27 26 27 27 29
				28 29 28 28 28 27 28 28 27 27 27 27 28 26 28 28 27 28 28 28 28 27 28 28 28 27 28 27 28 26 28 29
				29 28 27 28 28 28 28 28 27 27 27 28 27 26 27 28 29 27 27 28 27 28 28 28 27 27 27 28 27 26 27 29
				28 27 28 28 28 28 27 28 27 27 27 27 27 28 26 28 27 27 28 28 28 28 27 28 27 28 27 28 27 28 26 28
				27 28 28 27 28 28 28 28 27 27 27 28 28 27 26 28 28 28 28 27 28 28 28 28 27 27 27 27 28 27 26 27
				0 0 0>;

			PS_Config_Lmt_FW_Diff_P = <
				50 50 50 50 50 50 50 50 50 50 50 50 50 50 50 50 50 50 50 50 50 50 50 50 50 50 50 50 50 50 50 50
				50 50 50 50 50 50 50 50 50 50 50 50 50 50 50 50 50 50 50 50 50 50 50 50 50 50 50 50 50 50 50 50
				50 50 50 50 50 50 50 50 50 50 50 50 50 50 50 50 50 50 50 50 50 50 50 50 50 50 50 50 50 50 50 50
				50 50 50 50 50 50 50 50 50 50 50 50 50 50 50 50 50 50 50 50 50 50 50 50 50 50 50 50 50 50 50 50
				50 50 50 50 50 50 50 50 50 50 50 50 50 50 50 50 50 50 50 50 50 50 50 50 50 50 50 50 50 50 50 50
				50 50 50 50 50 50 50 50 50 50 50 50 50 50 50 50 50 50 50 50 50 50 50 50 50 50 50 50 50 50 50 50
				50 50 50 50 50 50 50 50 50 50 50 50 50 50 50 50 50 50 50 50 50 50 50 50 50 50 50 50 50 50 50 50
				50 50 50 50 50 50 50 50 50 50 50 50 50 50 50 50 50 50 50 50 50 50 50 50 50 50 50 50 50 50 50 50
				50 50 50 50 50 50 50 50 50 50 50 50 50 50 50 50 50 50 50 50 50 50 50 50 50 50 50 50 50 50 50 50
				50 50 50 50 50 50 50 50 50 50 50 50 50 50 50 50 50 50 50 50 50 50 50 50 50 50 50 50 50 50 50 50
				50 50 50 50 50 50 50 50 50 50 50 50 50 50 50 50 50 50 50 50 50 50 50 50 50 50 50 50 50 50 50 50
				50 50 50 50 50 50 50 50 50 50 50 50 50 50 50 50 50 50 50 50 50 50 50 50 50 50 50 50 50 50 50 50
				50 50 50 50 50 50 50 50 50 50 50 50 50 50 50 50 50 50 50 50 50 50 50 50 50 50 50 50 50 50 50 50
				50 50 50 50 50 50 50 50 50 50 50 50 50 50 50 50 50 50 50 50 50 50 50 50 50 50 50 50 50 50 50 50
				50 50 50 50 50 50 50 50 50 50 50 50 50 50 50 50 50 50 50 50 50 50 50 50 50 50 50 50 50 50 50 50
				50 50 50 50 50 50 50 50 50 50 50 50 50 50 50 50 50 50 50 50 50 50 50 50 50 50 50 50 50 50 50 50
				50 50 50 50 50 50 50 50 50 50 50 50 50 50 50 50 50 50 50 50 50 50 50 50 50 50 50 50 50 50 50 50
				50 50 50 50 50 50 50 50 50 50 50 50 50 50 50 50 50 50 50 50 50 50 50 50 50 50 50 50 50 50 50 50
				50 50 50 50 50 50 50 50 50 50 50 50 50 50 50 50 50 50 50 50 50 50 50 50 50 50 50 50 50 50 50 50
				50 50 50 50 50 50 50 50 50 50 50 50 50 50 50 50 50 50 50 50 50 50 50 50 50 50 50 50 50 50 50 50
				50 50 50 50 50 50 50 50 50 50 50 50 50 50 50 50 50 50 50 50 50 50 50 50 50 50 50 50 50 50 50 50
				50 50 50 50 50 50 50 50 50 50 50 50 50 50 50 50 50 50 50 50 50 50 50 50 50 50 50 50 50 50 50 50
				50 50 50 50 50 50 50 50 50 50 50 50 50 50 50 50 50 50 50 50 50 50 50 50 50 50 50 50 50 50 50 50
				50 50 50 50 50 50 50 50 50 50 50 50 50 50 50 50 50 50 50 50 50 50 50 50 50 50 50 50 50 50 50 50
				50 50 50 50 50 50 50 50 50 50 50 50 50 50 50 50 50 50 50 50 50 50 50 50 50 50 50 50 50 50 50 50
				50 50 50 50 50 50 50 50 50 50 50 50 50 50 50 50 50 50 50 50 50 50 50 50 50 50 50 50 50 50 50 50
				50 50 50 50 50 50 50 50 50 50 50 50 50 50 50 50 50 50 50 50 50 50 50 50 50 50 50 50 50 50 50 50
				50 50 50 50 50 50 50 50 50 50 50 50 50 50 50 50 50 50 50 50 50 50 50 50 50 50 50 50 50 50 50 50
				50 50 50 50 50 50 50 50 50 50 50 50 50 50 50 50 50 50 50 50 50 50 50 50 50 50 50 50 50 50 50 50
				50 50 50 50 50 50 50 50 50 50 50 50 50 50 50 50 50 50 50 50 50 50 50 50 50 50 50 50 50 50 50 50
				50 50 50 50 50 50 50 50 50 50 50 50 50 50 50 50 50 50 50 50 50 50 50 50 50 50 50 50 50 50 50 50
				50 50 50 50 50 50 50 50 50 50 50 50 50 50 50 50 50 50 50 50 50 50 50 50 50 50 50 50 50 50 50 50
				50 50 50 50 50 50 50 50 50 50 50 50 50 50 50 50 50 50 50 50 50 50 50 50 50 50 50 50 50 50 50 50
				50 50 50 50 50 50 50 50 50 50 50 50 50 50 50 50 50 50 50 50 50 50 50 50 50 50 50 50 50 50 50 50
				50 50 50 50 50 50 50 50 50 50 50 50 50 50 50 50 50 50 50 50 50 50 50 50 50 50 50 50 50 50 50 50
				50 50 50 50 50 50 50 50 50 50 50 50 50 50 50 50 50 50 50 50 50 50 50 50 50 50 50 50 50 50 50 50
				50 50 50 50 50 50 50 50 50 50 50 50 50 50 50 50 50 50 50 50 50 50 50 50 50 50 50 50 50 50 50 50
				50 50 50 50 50 50 50 50 50 50 50 50 50 50 50 50 50 50 50 50 50 50 50 50 50 50 50 50 50 50 50 50
				50 50 50 50 50 50 50 50 50 50 50 50 50 50 50 50 50 50 50 50 50 50 50 50 50 50 50 50 50 50 50 50
				50 50 50 50 50 50 50 50 50 50 50 50 50 50 50 50 50 50 50 50 50 50 50 50 50 50 50 50 50 50 50 50
				50 50 50 50 50 50 50 50 50 50 50 50 50 50 50 50 50 50 50 50 50 50 50 50 50 50 50 50 50 50 50 50
				50 50 50 50 50 50 50 50 50 50 50 50 50 50 50 50 50 50 50 50 50 50 50 50 50 50 50 50 50 50 50 50
				50 50 50 50 50 50 50 50 50 50 50 50 50 50 50 50 50 50 50 50 50 50 50 50 50 50 50 50 50 50 50 50
				50 50 50 50 50 50 50 50 50 50 50 50 50 50 50 50 50 50 50 50 50 50 50 50 50 50 50 50 50 50 50 50
				50 50 50 50 50 50 50 50 50 50 50 50 50 50 50 50 50 50 50 50 50 50 50 50 50 50 50 50 50 50 50 50
				50 50 50 50 50 50 50 50 50 50 50 50 50 50 50 50 50 50 50 50 50 50 50 50 50 50 50 50 50 50 50 50
				50 50 50 50 50 50 50 50 50 50 50 50 50 50 50 50 50 50 50 50 50 50 50 50 50 50 50 50 50 50 50 50
				50 50 50 50 50 50 50 50 50 50 50 50 50 50 50 50 50 50 50 50 50 50 50 50 50 50 50 50 50 50 50 50
				75 75 75>;

			PS_Config_Lmt_FW_Diff_N = <
				(-50) (-50) (-50) (-50) (-50) (-50) (-50) (-50) (-50) (-50) (-50) (-50) (-50) (-50) (-50) (-50) (-50) (-50) (-50) (-50) (-50) (-50) (-50) (-50) (-50) (-50) (-50) (-50) (-50) (-50) (-50) (-50)
				(-50) (-50) (-50) (-50) (-50) (-50) (-50) (-50) (-50) (-50) (-50) (-50) (-50) (-50) (-50) (-50) (-50) (-50) (-50) (-50) (-50) (-50) (-50) (-50) (-50) (-50) (-50) (-50) (-50) (-50) (-50) (-50)
				(-50) (-50) (-50) (-50) (-50) (-50) (-50) (-50) (-50) (-50) (-50) (-50) (-50) (-50) (-50) (-50) (-50) (-50) (-50) (-50) (-50) (-50) (-50) (-50) (-50) (-50) (-50) (-50) (-50) (-50) (-50) (-50)
				(-50) (-50) (-50) (-50) (-50) (-50) (-50) (-50) (-50) (-50) (-50) (-50) (-50) (-50) (-50) (-50) (-50) (-50) (-50) (-50) (-50) (-50) (-50) (-50) (-50) (-50) (-50) (-50) (-50) (-50) (-50) (-50)
				(-50) (-50) (-50) (-50) (-50) (-50) (-50) (-50) (-50) (-50) (-50) (-50) (-50) (-50) (-50) (-50) (-50) (-50) (-50) (-50) (-50) (-50) (-50) (-50) (-50) (-50) (-50) (-50) (-50) (-50) (-50) (-50)
				(-50) (-50) (-50) (-50) (-50) (-50) (-50) (-50) (-50) (-50) (-50) (-50) (-50) (-50) (-50) (-50) (-50) (-50) (-50) (-50) (-50) (-50) (-50) (-50) (-50) (-50) (-50) (-50) (-50) (-50) (-50) (-50)
				(-50) (-50) (-50) (-50) (-50) (-50) (-50) (-50) (-50) (-50) (-50) (-50) (-50) (-50) (-50) (-50) (-50) (-50) (-50) (-50) (-50) (-50) (-50) (-50) (-50) (-50) (-50) (-50) (-50) (-50) (-50) (-50)
				(-50) (-50) (-50) (-50) (-50) (-50) (-50) (-50) (-50) (-50) (-50) (-50) (-50) (-50) (-50) (-50) (-50) (-50) (-50) (-50) (-50) (-50) (-50) (-50) (-50) (-50) (-50) (-50) (-50) (-50) (-50) (-50)
				(-50) (-50) (-50) (-50) (-50) (-50) (-50) (-50) (-50) (-50) (-50) (-50) (-50) (-50) (-50) (-50) (-50) (-50) (-50) (-50) (-50) (-50) (-50) (-50) (-50) (-50) (-50) (-50) (-50) (-50) (-50) (-50)
				(-50) (-50) (-50) (-50) (-50) (-50) (-50) (-50) (-50) (-50) (-50) (-50) (-50) (-50) (-50) (-50) (-50) (-50) (-50) (-50) (-50) (-50) (-50) (-50) (-50) (-50) (-50) (-50) (-50) (-50) (-50) (-50)
				(-50) (-50) (-50) (-50) (-50) (-50) (-50) (-50) (-50) (-50) (-50) (-50) (-50) (-50) (-50) (-50) (-50) (-50) (-50) (-50) (-50) (-50) (-50) (-50) (-50) (-50) (-50) (-50) (-50) (-50) (-50) (-50)
				(-50) (-50) (-50) (-50) (-50) (-50) (-50) (-50) (-50) (-50) (-50) (-50) (-50) (-50) (-50) (-50) (-50) (-50) (-50) (-50) (-50) (-50) (-50) (-50) (-50) (-50) (-50) (-50) (-50) (-50) (-50) (-50)
				(-50) (-50) (-50) (-50) (-50) (-50) (-50) (-50) (-50) (-50) (-50) (-50) (-50) (-50) (-50) (-50) (-50) (-50) (-50) (-50) (-50) (-50) (-50) (-50) (-50) (-50) (-50) (-50) (-50) (-50) (-50) (-50)
				(-50) (-50) (-50) (-50) (-50) (-50) (-50) (-50) (-50) (-50) (-50) (-50) (-50) (-50) (-50) (-50) (-50) (-50) (-50) (-50) (-50) (-50) (-50) (-50) (-50) (-50) (-50) (-50) (-50) (-50) (-50) (-50)
				(-50) (-50) (-50) (-50) (-50) (-50) (-50) (-50) (-50) (-50) (-50) (-50) (-50) (-50) (-50) (-50) (-50) (-50) (-50) (-50) (-50) (-50) (-50) (-50) (-50) (-50) (-50) (-50) (-50) (-50) (-50) (-50)
				(-50) (-50) (-50) (-50) (-50) (-50) (-50) (-50) (-50) (-50) (-50) (-50) (-50) (-50) (-50) (-50) (-50) (-50) (-50) (-50) (-50) (-50) (-50) (-50) (-50) (-50) (-50) (-50) (-50) (-50) (-50) (-50)
				(-50) (-50) (-50) (-50) (-50) (-50) (-50) (-50) (-50) (-50) (-50) (-50) (-50) (-50) (-50) (-50) (-50) (-50) (-50) (-50) (-50) (-50) (-50) (-50) (-50) (-50) (-50) (-50) (-50) (-50) (-50) (-50)
				(-50) (-50) (-50) (-50) (-50) (-50) (-50) (-50) (-50) (-50) (-50) (-50) (-50) (-50) (-50) (-50) (-50) (-50) (-50) (-50) (-50) (-50) (-50) (-50) (-50) (-50) (-50) (-50) (-50) (-50) (-50) (-50)
				(-50) (-50) (-50) (-50) (-50) (-50) (-50) (-50) (-50) (-50) (-50) (-50) (-50) (-50) (-50) (-50) (-50) (-50) (-50) (-50) (-50) (-50) (-50) (-50) (-50) (-50) (-50) (-50) (-50) (-50) (-50) (-50)
				(-50) (-50) (-50) (-50) (-50) (-50) (-50) (-50) (-50) (-50) (-50) (-50) (-50) (-50) (-50) (-50) (-50) (-50) (-50) (-50) (-50) (-50) (-50) (-50) (-50) (-50) (-50) (-50) (-50) (-50) (-50) (-50)
				(-50) (-50) (-50) (-50) (-50) (-50) (-50) (-50) (-50) (-50) (-50) (-50) (-50) (-50) (-50) (-50) (-50) (-50) (-50) (-50) (-50) (-50) (-50) (-50) (-50) (-50) (-50) (-50) (-50) (-50) (-50) (-50)
				(-50) (-50) (-50) (-50) (-50) (-50) (-50) (-50) (-50) (-50) (-50) (-50) (-50) (-50) (-50) (-50) (-50) (-50) (-50) (-50) (-50) (-50) (-50) (-50) (-50) (-50) (-50) (-50) (-50) (-50) (-50) (-50)
				(-50) (-50) (-50) (-50) (-50) (-50) (-50) (-50) (-50) (-50) (-50) (-50) (-50) (-50) (-50) (-50) (-50) (-50) (-50) (-50) (-50) (-50) (-50) (-50) (-50) (-50) (-50) (-50) (-50) (-50) (-50) (-50)
				(-50) (-50) (-50) (-50) (-50) (-50) (-50) (-50) (-50) (-50) (-50) (-50) (-50) (-50) (-50) (-50) (-50) (-50) (-50) (-50) (-50) (-50) (-50) (-50) (-50) (-50) (-50) (-50) (-50) (-50) (-50) (-50)
				(-50) (-50) (-50) (-50) (-50) (-50) (-50) (-50) (-50) (-50) (-50) (-50) (-50) (-50) (-50) (-50) (-50) (-50) (-50) (-50) (-50) (-50) (-50) (-50) (-50) (-50) (-50) (-50) (-50) (-50) (-50) (-50)
				(-50) (-50) (-50) (-50) (-50) (-50) (-50) (-50) (-50) (-50) (-50) (-50) (-50) (-50) (-50) (-50) (-50) (-50) (-50) (-50) (-50) (-50) (-50) (-50) (-50) (-50) (-50) (-50) (-50) (-50) (-50) (-50)
				(-50) (-50) (-50) (-50) (-50) (-50) (-50) (-50) (-50) (-50) (-50) (-50) (-50) (-50) (-50) (-50) (-50) (-50) (-50) (-50) (-50) (-50) (-50) (-50) (-50) (-50) (-50) (-50) (-50) (-50) (-50) (-50)
				(-50) (-50) (-50) (-50) (-50) (-50) (-50) (-50) (-50) (-50) (-50) (-50) (-50) (-50) (-50) (-50) (-50) (-50) (-50) (-50) (-50) (-50) (-50) (-50) (-50) (-50) (-50) (-50) (-50) (-50) (-50) (-50)
				(-50) (-50) (-50) (-50) (-50) (-50) (-50) (-50) (-50) (-50) (-50) (-50) (-50) (-50) (-50) (-50) (-50) (-50) (-50) (-50) (-50) (-50) (-50) (-50) (-50) (-50) (-50) (-50) (-50) (-50) (-50) (-50)
				(-50) (-50) (-50) (-50) (-50) (-50) (-50) (-50) (-50) (-50) (-50) (-50) (-50) (-50) (-50) (-50) (-50) (-50) (-50) (-50) (-50) (-50) (-50) (-50) (-50) (-50) (-50) (-50) (-50) (-50) (-50) (-50)
				(-50) (-50) (-50) (-50) (-50) (-50) (-50) (-50) (-50) (-50) (-50) (-50) (-50) (-50) (-50) (-50) (-50) (-50) (-50) (-50) (-50) (-50) (-50) (-50) (-50) (-50) (-50) (-50) (-50) (-50) (-50) (-50)
				(-50) (-50) (-50) (-50) (-50) (-50) (-50) (-50) (-50) (-50) (-50) (-50) (-50) (-50) (-50) (-50) (-50) (-50) (-50) (-50) (-50) (-50) (-50) (-50) (-50) (-50) (-50) (-50) (-50) (-50) (-50) (-50)
				(-50) (-50) (-50) (-50) (-50) (-50) (-50) (-50) (-50) (-50) (-50) (-50) (-50) (-50) (-50) (-50) (-50) (-50) (-50) (-50) (-50) (-50) (-50) (-50) (-50) (-50) (-50) (-50) (-50) (-50) (-50) (-50)
				(-50) (-50) (-50) (-50) (-50) (-50) (-50) (-50) (-50) (-50) (-50) (-50) (-50) (-50) (-50) (-50) (-50) (-50) (-50) (-50) (-50) (-50) (-50) (-50) (-50) (-50) (-50) (-50) (-50) (-50) (-50) (-50)
				(-50) (-50) (-50) (-50) (-50) (-50) (-50) (-50) (-50) (-50) (-50) (-50) (-50) (-50) (-50) (-50) (-50) (-50) (-50) (-50) (-50) (-50) (-50) (-50) (-50) (-50) (-50) (-50) (-50) (-50) (-50) (-50)
				(-50) (-50) (-50) (-50) (-50) (-50) (-50) (-50) (-50) (-50) (-50) (-50) (-50) (-50) (-50) (-50) (-50) (-50) (-50) (-50) (-50) (-50) (-50) (-50) (-50) (-50) (-50) (-50) (-50) (-50) (-50) (-50)
				(-50) (-50) (-50) (-50) (-50) (-50) (-50) (-50) (-50) (-50) (-50) (-50) (-50) (-50) (-50) (-50) (-50) (-50) (-50) (-50) (-50) (-50) (-50) (-50) (-50) (-50) (-50) (-50) (-50) (-50) (-50) (-50)
				(-50) (-50) (-50) (-50) (-50) (-50) (-50) (-50) (-50) (-50) (-50) (-50) (-50) (-50) (-50) (-50) (-50) (-50) (-50) (-50) (-50) (-50) (-50) (-50) (-50) (-50) (-50) (-50) (-50) (-50) (-50) (-50)
				(-50) (-50) (-50) (-50) (-50) (-50) (-50) (-50) (-50) (-50) (-50) (-50) (-50) (-50) (-50) (-50) (-50) (-50) (-50) (-50) (-50) (-50) (-50) (-50) (-50) (-50) (-50) (-50) (-50) (-50) (-50) (-50)
				(-50) (-50) (-50) (-50) (-50) (-50) (-50) (-50) (-50) (-50) (-50) (-50) (-50) (-50) (-50) (-50) (-50) (-50) (-50) (-50) (-50) (-50) (-50) (-50) (-50) (-50) (-50) (-50) (-50) (-50) (-50) (-50)
				(-50) (-50) (-50) (-50) (-50) (-50) (-50) (-50) (-50) (-50) (-50) (-50) (-50) (-50) (-50) (-50) (-50) (-50) (-50) (-50) (-50) (-50) (-50) (-50) (-50) (-50) (-50) (-50) (-50) (-50) (-50) (-50)
				(-50) (-50) (-50) (-50) (-50) (-50) (-50) (-50) (-50) (-50) (-50) (-50) (-50) (-50) (-50) (-50) (-50) (-50) (-50) (-50) (-50) (-50) (-50) (-50) (-50) (-50) (-50) (-50) (-50) (-50) (-50) (-50)
				(-50) (-50) (-50) (-50) (-50) (-50) (-50) (-50) (-50) (-50) (-50) (-50) (-50) (-50) (-50) (-50) (-50) (-50) (-50) (-50) (-50) (-50) (-50) (-50) (-50) (-50) (-50) (-50) (-50) (-50) (-50) (-50)
				(-50) (-50) (-50) (-50) (-50) (-50) (-50) (-50) (-50) (-50) (-50) (-50) (-50) (-50) (-50) (-50) (-50) (-50) (-50) (-50) (-50) (-50) (-50) (-50) (-50) (-50) (-50) (-50) (-50) (-50) (-50) (-50)
				(-50) (-50) (-50) (-50) (-50) (-50) (-50) (-50) (-50) (-50) (-50) (-50) (-50) (-50) (-50) (-50) (-50) (-50) (-50) (-50) (-50) (-50) (-50) (-50) (-50) (-50) (-50) (-50) (-50) (-50) (-50) (-50)
				(-50) (-50) (-50) (-50) (-50) (-50) (-50) (-50) (-50) (-50) (-50) (-50) (-50) (-50) (-50) (-50) (-50) (-50) (-50) (-50) (-50) (-50) (-50) (-50) (-50) (-50) (-50) (-50) (-50) (-50) (-50) (-50)
				(-50) (-50) (-50) (-50) (-50) (-50) (-50) (-50) (-50) (-50) (-50) (-50) (-50) (-50) (-50) (-50) (-50) (-50) (-50) (-50) (-50) (-50) (-50) (-50) (-50) (-50) (-50) (-50) (-50) (-50) (-50) (-50)
				(-50) (-50) (-50) (-50) (-50) (-50) (-50) (-50) (-50) (-50) (-50) (-50) (-50) (-50) (-50) (-50) (-50) (-50) (-50) (-50) (-50) (-50) (-50) (-50) (-50) (-50) (-50) (-50) (-50) (-50) (-50) (-50)
				(-75) (-75) (-75)>;

			PS_Config_Lmt_PenTipX_FW_Raw_P = <
				380 380 380 380 380 380 380 380 380 380 380 380 380 380 380 380 380 380 380 380 380 380 380 380 380 380 380 380 380 380 380 380
				380 380 380 380 380 380 380 380 380 380 380 380 380 380 380 380 380 380 380 380 380 380 380 380 380 380 380 380 380 380 380 380
				380 380 380 380 380 380 380 380 380 380 380 380 380 380 380 380 380 380 380 380 380 380 380 380 380 380 380 380 380 380 380 380
				380 380 380 380 380 380 380 380 380 380 380 380 380 380 380 380 380 380 380 380 380 380 380 380 380 380 380 380 380 380 380 380
				380 380 380 380 380 380 380 380 380 380 380 380 380 380 380 380 380 380 380 380 380 380 380 380 380 380 380 380 380 380 380 380
				380 380 380 380 380 380 380 380 380 380 380 380 380 380 380 380 380 380 380 380 380 380 380 380 380 380 380 380 380 380 380 380>;

			PS_Config_Lmt_PenTipX_FW_Raw_N = <
				0 0 0 0 0 0 0 0 0 0 0 0 0 0 0 0 0 0 0 0 0 0 0 0 0 0 0 0 0 0 0 0
				0 0 0 0 0 0 0 0 0 0 0 0 0 0 0 0 0 0 0 0 0 0 0 0 0 0 0 0 0 0 0 0
				0 0 0 0 0 0 0 0 0 0 0 0 0 0 0 0 0 0 0 0 0 0 0 0 0 0 0 0 0 0 0 0
				0 0 0 0 0 0 0 0 0 0 0 0 0 0 0 0 0 0 0 0 0 0 0 0 0 0 0 0 0 0 0 0
				0 0 0 0 0 0 0 0 0 0 0 0 0 0 0 0 0 0 0 0 0 0 0 0 0 0 0 0 0 0 0 0
				0 0 0 0 0 0 0 0 0 0 0 0 0 0 0 0 0 0 0 0 0 0 0 0 0 0 0 0 0 0 0 0>;

			PS_Config_Lmt_PenTipY_FW_Raw_P = <
				380 380 380 380
				380 380 380 380
				380 380 380 380
				380 380 380 380
				380 380 380 380
				380 380 380 380
				380 380 380 380
				380 380 380 380
				380 380 380 380
				380 380 380 380
				380 380 380 380
				380 380 380 380
				380 380 380 380
				380 380 380 380
				380 380 380 380
				380 380 380 380
				380 380 380 380
				380 380 380 380
				380 380 380 380
				380 380 380 380
				380 380 380 380
				380 380 380 380
				380 380 380 380
				380 380 380 380
				380 380 380 380
				380 380 380 380
				380 380 380 380
				380 380 380 380
				380 380 380 380
				380 380 380 380
				380 380 380 380
				380 380 380 380
				380 380 380 380
				380 380 380 380
				380 380 380 380
				380 380 380 380
				380 380 380 380
				380 380 380 380
				380 380 380 380
				380 380 380 380
				380 380 380 380
				380 380 380 380
				380 380 380 380
				380 380 380 380
				380 380 380 380
				380 380 380 380
				380 380 380 380
				380 380 380 380>;

			PS_Config_Lmt_PenTipY_FW_Raw_N = <
				0 0 0 0
				0 0 0 0
				0 0 0 0
				0 0 0 0
				0 0 0 0
				0 0 0 0
				0 0 0 0
				0 0 0 0
				0 0 0 0
				0 0 0 0
				0 0 0 0
				0 0 0 0
				0 0 0 0
				0 0 0 0
				0 0 0 0
				0 0 0 0
				0 0 0 0
				0 0 0 0
				0 0 0 0
				0 0 0 0
				0 0 0 0
				0 0 0 0
				0 0 0 0
				0 0 0 0
				0 0 0 0
				0 0 0 0
				0 0 0 0
				0 0 0 0
				0 0 0 0
				0 0 0 0
				0 0 0 0
				0 0 0 0
				0 0 0 0
				0 0 0 0
				0 0 0 0
				0 0 0 0
				0 0 0 0
				0 0 0 0
				0 0 0 0
				0 0 0 0
				0 0 0 0
				0 0 0 0
				0 0 0 0
				0 0 0 0
				0 0 0 0
				0 0 0 0
				0 0 0 0
				0 0 0 0>;

			PS_Config_Lmt_PenRingX_FW_Raw_P = <
				380 380 380 380 380 380 380 380 380 380 380 380 380 380 380 380 380 380 380 380 380 380 380 380 380 380 380 380 380 380 380 380
				380 380 380 380 380 380 380 380 380 380 380 380 380 380 380 380 380 380 380 380 380 380 380 380 380 380 380 380 380 380 380 380
				380 380 380 380 380 380 380 380 380 380 380 380 380 380 380 380 380 380 380 380 380 380 380 380 380 380 380 380 380 380 380 380
				380 380 380 380 380 380 380 380 380 380 380 380 380 380 380 380 380 380 380 380 380 380 380 380 380 380 380 380 380 380 380 380
				380 380 380 380 380 380 380 380 380 380 380 380 380 380 380 380 380 380 380 380 380 380 380 380 380 380 380 380 380 380 380 380
				380 380 380 380 380 380 380 380 380 380 380 380 380 380 380 380 380 380 380 380 380 380 380 380 380 380 380 380 380 380 380 380>;

			PS_Config_Lmt_PenRingX_FW_Raw_N = <
				0 0 0 0 0 0 0 0 0 0 0 0 0 0 0 0 0 0 0 0 0 0 0 0 0 0 0 0 0 0 0 0
				0 0 0 0 0 0 0 0 0 0 0 0 0 0 0 0 0 0 0 0 0 0 0 0 0 0 0 0 0 0 0 0
				0 0 0 0 0 0 0 0 0 0 0 0 0 0 0 0 0 0 0 0 0 0 0 0 0 0 0 0 0 0 0 0
				0 0 0 0 0 0 0 0 0 0 0 0 0 0 0 0 0 0 0 0 0 0 0 0 0 0 0 0 0 0 0 0
				0 0 0 0 0 0 0 0 0 0 0 0 0 0 0 0 0 0 0 0 0 0 0 0 0 0 0 0 0 0 0 0
				0 0 0 0 0 0 0 0 0 0 0 0 0 0 0 0 0 0 0 0 0 0 0 0 0 0 0 0 0 0 0 0>;

			PS_Config_Lmt_PenRingY_FW_Raw_P = <
				380 380 380 380
				380 380 380 380
				380 380 380 380
				380 380 380 380
				380 380 380 380
				380 380 380 380
				380 380 380 380
				380 380 380 380
				380 380 380 380
				380 380 380 380
				380 380 380 380
				380 380 380 380
				380 380 380 380
				380 380 380 380
				380 380 380 380
				380 380 380 380
				380 380 380 380
				380 380 380 380
				380 380 380 380
				380 380 380 380
				380 380 380 380
				380 380 380 380
				380 380 380 380
				380 380 380 380
				380 380 380 380
				380 380 380 380
				380 380 380 380
				380 380 380 380
				380 380 380 380
				380 380 380 380
				380 380 380 380
				380 380 380 380
				380 380 380 380
				380 380 380 380
				380 380 380 380
				380 380 380 380
				380 380 380 380
				380 380 380 380
				380 380 380 380
				380 380 380 380
				380 380 380 380
				380 380 380 380
				380 380 380 380
				380 380 380 380
				380 380 380 380
				380 380 380 380
				380 380 380 380
				380 380 380 380>;

			PS_Config_Lmt_PenRingY_FW_Raw_N = <
				0 0 0 0
				0 0 0 0
				0 0 0 0
				0 0 0 0
				0 0 0 0
				0 0 0 0
				0 0 0 0
				0 0 0 0
				0 0 0 0
				0 0 0 0
				0 0 0 0
				0 0 0 0
				0 0 0 0
				0 0 0 0
				0 0 0 0
				0 0 0 0
				0 0 0 0
				0 0 0 0
				0 0 0 0
				0 0 0 0
				0 0 0 0
				0 0 0 0
				0 0 0 0
				0 0 0 0
				0 0 0 0
				0 0 0 0
				0 0 0 0
				0 0 0 0
				0 0 0 0
				0 0 0 0
				0 0 0 0
				0 0 0 0
				0 0 0 0
				0 0 0 0
				0 0 0 0
				0 0 0 0
				0 0 0 0
				0 0 0 0
				0 0 0 0
				0 0 0 0
				0 0 0 0
				0 0 0 0
				0 0 0 0
				0 0 0 0
				0 0 0 0
				0 0 0 0
				0 0 0 0
				0 0 0 0>;

			PS_Config_Lmt_PenTipX_FW_Diff_P = <
				580 580 580 580 580 580 580 580 580 580 580 580 580 580 580 580 580 580 580 580 580 580 580 580 580 580 580 580 580 580 580 580
				580 580 580 580 580 580 580 580 580 580 580 580 580 580 580 580 580 580 580 580 580 580 580 580 580 580 580 580 580 580 580 580
				580 580 580 580 580 580 580 580 580 580 580 580 580 580 580 580 580 580 580 580 580 580 580 580 580 580 580 580 580 580 580 580
				580 580 580 580 580 580 580 580 580 580 580 580 580 580 580 580 580 580 580 580 580 580 580 580 580 580 580 580 580 580 580 580
				580 580 580 580 580 580 580 580 580 580 580 580 580 580 580 580 580 580 580 580 580 580 580 580 580 580 580 580 580 580 580 580
				580 580 580 580 580 580 580 580 580 580 580 580 580 580 580 580 580 580 580 580 580 580 580 580 580 580 580 580 580 580 580 580>;

			PS_Config_Lmt_PenTipX_FW_Diff_N = <
				(-580) (-580) (-580) (-580) (-580) (-580) (-580) (-580) (-580) (-580) (-580) (-580) (-580) (-580) (-580) (-580) (-580) (-580) (-580) (-580) (-580) (-580) (-580) (-580) (-580) (-580) (-580) (-580) (-580) (-580) (-580) (-580)
				(-580) (-580) (-580) (-580) (-580) (-580) (-580) (-580) (-580) (-580) (-580) (-580) (-580) (-580) (-580) (-580) (-580) (-580) (-580) (-580) (-580) (-580) (-580) (-580) (-580) (-580) (-580) (-580) (-580) (-580) (-580) (-580)
				(-580) (-580) (-580) (-580) (-580) (-580) (-580) (-580) (-580) (-580) (-580) (-580) (-580) (-580) (-580) (-580) (-580) (-580) (-580) (-580) (-580) (-580) (-580) (-580) (-580) (-580) (-580) (-580) (-580) (-580) (-580) (-580)
				(-580) (-580) (-580) (-580) (-580) (-580) (-580) (-580) (-580) (-580) (-580) (-580) (-580) (-580) (-580) (-580) (-580) (-580) (-580) (-580) (-580) (-580) (-580) (-580) (-580) (-580) (-580) (-580) (-580) (-580) (-580) (-580)
				(-580) (-580) (-580) (-580) (-580) (-580) (-580) (-580) (-580) (-580) (-580) (-580) (-580) (-580) (-580) (-580) (-580) (-580) (-580) (-580) (-580) (-580) (-580) (-580) (-580) (-580) (-580) (-580) (-580) (-580) (-580) (-580)
				(-580) (-580) (-580) (-580) (-580) (-580) (-580) (-580) (-580) (-580) (-580) (-580) (-580) (-580) (-580) (-580) (-580) (-580) (-580) (-580) (-580) (-580) (-580) (-580) (-580) (-580) (-580) (-580) (-580) (-580) (-580) (-580)>;

			PS_Config_Lmt_PenTipY_FW_Diff_P = <
				580 580 580 580
				580 580 580 580
				580 580 580 580
				580 580 580 580
				580 580 580 580
				580 580 580 580
				580 580 580 580
				580 580 580 580
				580 580 580 580
				580 580 580 580
				580 580 580 580
				580 580 580 580
				580 580 580 580
				580 580 580 580
				580 580 580 580
				580 580 580 580
				580 580 580 580
				580 580 580 580
				580 580 580 580
				580 580 580 580
				580 580 580 580
				580 580 580 580
				580 580 580 580
				580 580 580 580
				580 580 580 580
				580 580 580 580
				580 580 580 580
				580 580 580 580
				580 580 580 580
				580 580 580 580
				580 580 580 580
				580 580 580 580
				580 580 580 580
				580 580 580 580
				580 580 580 580
				580 580 580 580
				580 580 580 580
				580 580 580 580
				580 580 580 580
				580 580 580 580
				580 580 580 580
				580 580 580 580
				580 580 580 580
				580 580 580 580
				580 580 580 580
				580 580 580 580
				580 580 580 580
				580 580 580 580>;

			PS_Config_Lmt_PenTipY_FW_Diff_N = <
				(-580) (-580) (-580) (-580)
				(-580) (-580) (-580) (-580)
				(-580) (-580) (-580) (-580)
				(-580) (-580) (-580) (-580)
				(-580) (-580) (-580) (-580)
				(-580) (-580) (-580) (-580)
				(-580) (-580) (-580) (-580)
				(-580) (-580) (-580) (-580)
				(-580) (-580) (-580) (-580)
				(-580) (-580) (-580) (-580)
				(-580) (-580) (-580) (-580)
				(-580) (-580) (-580) (-580)
				(-580) (-580) (-580) (-580)
				(-580) (-580) (-580) (-580)
				(-580) (-580) (-580) (-580)
				(-580) (-580) (-580) (-580)
				(-580) (-580) (-580) (-580)
				(-580) (-580) (-580) (-580)
				(-580) (-580) (-580) (-580)
				(-580) (-580) (-580) (-580)
				(-580) (-580) (-580) (-580)
				(-580) (-580) (-580) (-580)
				(-580) (-580) (-580) (-580)
				(-580) (-580) (-580) (-580)
				(-580) (-580) (-580) (-580)
				(-580) (-580) (-580) (-580)
				(-580) (-580) (-580) (-580)
				(-580) (-580) (-580) (-580)
				(-580) (-580) (-580) (-580)
				(-580) (-580) (-580) (-580)
				(-580) (-580) (-580) (-580)
				(-580) (-580) (-580) (-580)
				(-580) (-580) (-580) (-580)
				(-580) (-580) (-580) (-580)
				(-580) (-580) (-580) (-580)
				(-580) (-580) (-580) (-580)
				(-580) (-580) (-580) (-580)
				(-580) (-580) (-580) (-580)
				(-580) (-580) (-580) (-580)
				(-580) (-580) (-580) (-580)
				(-580) (-580) (-580) (-580)
				(-580) (-580) (-580) (-580)
				(-580) (-580) (-580) (-580)
				(-580) (-580) (-580) (-580)
				(-580) (-580) (-580) (-580)
				(-580) (-580) (-580) (-580)
				(-580) (-580) (-580) (-580)
				(-580) (-580) (-580) (-580)>;

			PS_Config_Lmt_PenRingX_FW_Diff_P = <
				580 580 580 580 580 580 580 580 580 580 580 580 580 580 580 580 580 580 580 580 580 580 580 580 580 580 580 580 580 580 580 580
				580 580 580 580 580 580 580 580 580 580 580 580 580 580 580 580 580 580 580 580 580 580 580 580 580 580 580 580 580 580 580 580
				580 580 580 580 580 580 580 580 580 580 580 580 580 580 580 580 580 580 580 580 580 580 580 580 580 580 580 580 580 580 580 580
				580 580 580 580 580 580 580 580 580 580 580 580 580 580 580 580 580 580 580 580 580 580 580 580 580 580 580 580 580 580 580 580
				580 580 580 580 580 580 580 580 580 580 580 580 580 580 580 580 580 580 580 580 580 580 580 580 580 580 580 580 580 580 580 580
				580 580 580 580 580 580 580 580 580 580 580 580 580 580 580 580 580 580 580 580 580 580 580 580 580 580 580 580 580 580 580 580>;

			PS_Config_Lmt_PenRingX_FW_Diff_N = <
				(-580) (-580) (-580) (-580) (-580) (-580) (-580) (-580) (-580) (-580) (-580) (-580) (-580) (-580) (-580) (-580) (-580) (-580) (-580) (-580) (-580) (-580) (-580) (-580) (-580) (-580) (-580) (-580) (-580) (-580) (-580) (-580)
				(-580) (-580) (-580) (-580) (-580) (-580) (-580) (-580) (-580) (-580) (-580) (-580) (-580) (-580) (-580) (-580) (-580) (-580) (-580) (-580) (-580) (-580) (-580) (-580) (-580) (-580) (-580) (-580) (-580) (-580) (-580) (-580)
				(-580) (-580) (-580) (-580) (-580) (-580) (-580) (-580) (-580) (-580) (-580) (-580) (-580) (-580) (-580) (-580) (-580) (-580) (-580) (-580) (-580) (-580) (-580) (-580) (-580) (-580) (-580) (-580) (-580) (-580) (-580) (-580)
				(-580) (-580) (-580) (-580) (-580) (-580) (-580) (-580) (-580) (-580) (-580) (-580) (-580) (-580) (-580) (-580) (-580) (-580) (-580) (-580) (-580) (-580) (-580) (-580) (-580) (-580) (-580) (-580) (-580) (-580) (-580) (-580)
				(-580) (-580) (-580) (-580) (-580) (-580) (-580) (-580) (-580) (-580) (-580) (-580) (-580) (-580) (-580) (-580) (-580) (-580) (-580) (-580) (-580) (-580) (-580) (-580) (-580) (-580) (-580) (-580) (-580) (-580) (-580) (-580)
				(-580) (-580) (-580) (-580) (-580) (-580) (-580) (-580) (-580) (-580) (-580) (-580) (-580) (-580) (-580) (-580) (-580) (-580) (-580) (-580) (-580) (-580) (-580) (-580) (-580) (-580) (-580) (-580) (-580) (-580) (-580) (-580)>;

			PS_Config_Lmt_PenRingY_FW_Diff_P = <
				580 580 580 580
				580 580 580 580
				580 580 580 580
				580 580 580 580
				580 580 580 580
				580 580 580 580
				580 580 580 580
				580 580 580 580
				580 580 580 580
				580 580 580 580
				580 580 580 580
				580 580 580 580
				580 580 580 580
				580 580 580 580
				580 580 580 580
				580 580 580 580
				580 580 580 580
				580 580 580 580
				580 580 580 580
				580 580 580 580
				580 580 580 580
				580 580 580 580
				580 580 580 580
				580 580 580 580
				580 580 580 580
				580 580 580 580
				580 580 580 580
				580 580 580 580
				580 580 580 580
				580 580 580 580
				580 580 580 580
				580 580 580 580
				580 580 580 580
				580 580 580 580
				580 580 580 580
				580 580 580 580
				580 580 580 580
				580 580 580 580
				580 580 580 580
				580 580 580 580
				580 580 580 580
				580 580 580 580
				580 580 580 580
				580 580 580 580
				580 580 580 580
				580 580 580 580
				580 580 580 580
				580 580 580 580>;

			PS_Config_Lmt_PenRingY_FW_Diff_N = <
				(-580) (-580) (-580) (-580)
				(-580) (-580) (-580) (-580)
				(-580) (-580) (-580) (-580)
				(-580) (-580) (-580) (-580)
				(-580) (-580) (-580) (-580)
				(-580) (-580) (-580) (-580)
				(-580) (-580) (-580) (-580)
				(-580) (-580) (-580) (-580)
				(-580) (-580) (-580) (-580)
				(-580) (-580) (-580) (-580)
				(-580) (-580) (-580) (-580)
				(-580) (-580) (-580) (-580)
				(-580) (-580) (-580) (-580)
				(-580) (-580) (-580) (-580)
				(-580) (-580) (-580) (-580)
				(-580) (-580) (-580) (-580)
				(-580) (-580) (-580) (-580)
				(-580) (-580) (-580) (-580)
				(-580) (-580) (-580) (-580)
				(-580) (-580) (-580) (-580)
				(-580) (-580) (-580) (-580)
				(-580) (-580) (-580) (-580)
				(-580) (-580) (-580) (-580)
				(-580) (-580) (-580) (-580)
				(-580) (-580) (-580) (-580)
				(-580) (-580) (-580) (-580)
				(-580) (-580) (-580) (-580)
				(-580) (-580) (-580) (-580)
				(-580) (-580) (-580) (-580)
				(-580) (-580) (-580) (-580)
				(-580) (-580) (-580) (-580)
				(-580) (-580) (-580) (-580)
				(-580) (-580) (-580) (-580)
				(-580) (-580) (-580) (-580)
				(-580) (-580) (-580) (-580)
				(-580) (-580) (-580) (-580)
				(-580) (-580) (-580) (-580)
				(-580) (-580) (-580) (-580)
				(-580) (-580) (-580) (-580)
				(-580) (-580) (-580) (-580)
				(-580) (-580) (-580) (-580)
				(-580) (-580) (-580) (-580)
				(-580) (-580) (-580) (-580)
				(-580) (-580) (-580) (-580)
				(-580) (-580) (-580) (-580)
				(-580) (-580) (-580) (-580)
				(-580) (-580) (-580) (-580)
				(-580) (-580) (-580) (-580)>;

			PS_Config_Diff_Test_Frame = <50>;
		};
	};
};

&i2c3 {
	ext_buck_lp4@57 {
		regulator-name ="ext_buck_vdd2";
		regulator-min-microvolt = <300000>;
		regulator-max-microvolt = <1300000>;
		vsel_pin = <0>;
	};

	ext_buck_lp4x@50 {
		regulator-name ="ext_buck_vddq";
		regulator-min-microvolt = <300000>;
		regulator-max-microvolt = <1300000>;
		vsel_pin = <1>;
	};

	Semtech_sx933x@28 {
		compatible = "Semtech,sx933x";
		reg = <0x28>;
		interrupt-parent = <&pio>;
		interrupts = <11 IRQ_TYPE_EDGE_FALLING 11 0>;
		Semtech,nirq-gpio = <&pio 11 0x00>;
		status = "okay";
	};
	hall_1:hall_1@33 {
		compatible = "mediatek,hall";
		reg = <0x33>;
		interrupt-parent = <&pio>;
		interrupts = <7 IRQ_TYPE_EDGE_BOTH 7 0>;
		hall,irq-gpio = <&pio 7 0x00>;
		status = "okay";
	};

	mm8013c10@55 {
		compatible = "mediatek,mm8013c10";
		reg = <0x55>;

		status = "okay";
	};
};

&i2c6 {
	usb_type_c@4e {
		compatible = "mediatek,usb_type_c";
		reg = <0x4e>;

		status = "okay";
	};
};

/* TOUCH start */
&touch {
	tpd-resolution = <1200 1920>;
	use-tpd-button = <0>;
	tpd-key-num = <3>;
	tpd-key-local= <139 172 158 0>;
	tpd-key-dim-local = <90 883 100 40 230
				 883 100 40 370 883 100 40 0 0 0 0>;
	tpd-max-touch-num = <10>;
	tpd-filter-enable = <0>;
	tpd-filter-pixel-density = <106>;
	tpd-filter-custom-prameters = <0 0 0 0 0 0 0 0 0 0 0 0>;
	tpd-filter-custom-speed = <0 0 0>;
	pinctrl-names = "default", "state_eint_as_int", "state_eint_output0",
		"state_eint_output1", "state_rst_output0", "state_rst_output1";
	pinctrl-0 = <&ctp_pins_default>;
	pinctrl-1 = <&ctp_pins_eint_as_int>;
	pinctrl-2 = <&ctp_pins_eint_output0>;
	pinctrl-3 = <&ctp_pins_eint_output1>;
	pinctrl-4 = <&ctp_pins_rst_output0>;
	pinctrl-5 = <&ctp_pins_rst_output1>;
	status = "okay";
};
&pio {
	ctp_pins_default: eint0default {
	};
	ctp_pins_eint_as_int: eint@0 {
		pins_cmd_dat {
			pinmux = <PINMUX_GPIO10__FUNC_GPIO10>;
			slew-rate = <0>;
			bias-disable;
		};
	};
	ctp_pins_eint_output0: eintoutput0 {
		pins_cmd_dat {
			pinmux = <PINMUX_GPIO10__FUNC_GPIO10>;
			slew-rate = <1>;
			output-low;
		};
	};
	ctp_pins_eint_output1: eintoutput1 {
		pins_cmd_dat {
			pinmux = <PINMUX_GPIO10__FUNC_GPIO10>;
			slew-rate = <1>;
			output-high;
		};
	};
	ctp_pins_rst_output0: rstoutput0 {
		pins_cmd_dat {
			pinmux = <PINMUX_GPIO172__FUNC_GPIO172>;
			slew-rate = <1>;
			output-low;
		};
	};
	ctp_pins_rst_output1: rstoutput1 {
		pins_cmd_dat {
			pinmux = <PINMUX_GPIO172__FUNC_GPIO172>;
			slew-rate = <1>;
			output-high;
		};
	};
};
/* TOUCH end */

&i2c5 {
	bq25601@6B {
		status = "okay";
		compatible = "ti,bq25601";
		reg = <0x6B>;

		charger_name = "primary_chg";

		ti,bq2560x,usb-vlim = <4600>;
		ti,bq2560x,usb-ilim = <500>;
		ti,bq2560x,usb-vreg = <4400>;
		ti,bq2560x,usb-ichg = <500>;
		ti,bq2560x,precharge-current = <256>;
		ti,bq2560x,termination-current = <180>;
		ti,bq2560x,boost-voltage = <4998>;
		ti,bq2560x,boost-current = <1200>;
		ti,bq2560x,enable_term;
		ti,bq2560x,stat-pin-ctrl = <3>;
		ti,bq2560x,vac-ovp-threshold = <6500>;

		otg_vbus: usb-otg-vbus {
			regulator-compatible = "usb-otg-vbus";
			regulator-name = "usb-otg-vbus";
			regulator-min-microvolt = <5000000>;
			regulator-max-microvolt = <5000000>;
		};
	};
	    sgm37603a_bl@36 {

        compatible = "mediatek,sgm37603a_bl";

        reg = <0x36>;
	status = "okay";
    };

    ktz8864a_bl@11 {
        compatible = "mediatek,ktz8864a_bl";
        reg = <0x11>;
        status = "okay";
    };

	lcd_bias@3e {
		compatible = "mediatek,lcd_bias";
		reg = <0x3e>;
		status = "okay";
	};
    aw881xx_smartpa@34 {
        status = "okay";
        compatible = "awinic,aw881xx_smartpa_l";
        reg = <0x34>;
        reset-gpio = <&pio 174 0>;
        irq-gpio = <&pio 26 0>;
        monitor-flag = <1>;
        monitor-timer-val = <30000>;
        sound-channel = "left";
    };
    aw881xx_smartpa@37 {
        status = "okay";
        compatible = "awinic,aw881xx_smartpa_r";
        reg = <0x37>;
        irq-gpio = <&pio 27 0>;
        monitor-flag = <1>;
        monitor-timer-val = <30000>;
        sound-channel = "right";
    };
};

/* CONSYS GPIO standardization */
&pio {
	consys_pins_default: consys_default {
	};
	gpslna_pins_init: gpslna@0 {
		pins_cmd_dat {
			pinmux = <PINMUX_GPIO91__FUNC_GPIO91>;
			slew-rate = <0>;
			bias-disable;
			output-low;
		};
	};
	gpslna_pins_oh: gpslna@1 {
		pins_cmd_dat {
			pinmux = <PINMUX_GPIO91__FUNC_GPIO91>;
			slew-rate = <1>;
			output-high;
		};
	};
	gpslna_pins_ol: gpslna@2 {
		pins_cmd_dat {
			pinmux = <PINMUX_GPIO91__FUNC_GPIO91>;
			slew-rate = <1>;
			output-low;
		};
	};
};
&consys {
	pinctrl-names = "default", "gps_lna_state_init",
		"gps_lna_state_oh", "gps_lna_state_ol";
	pinctrl-0 = <&consys_pins_default>;
	pinctrl-1 = <&gpslna_pins_init>;
	pinctrl-2 = <&gpslna_pins_oh>;
	pinctrl-3 = <&gpslna_pins_ol>;
	status = "okay";
};
/* CONSYS end */

/* accdet start */
&accdet {
	accdet-mic-vol = <6>;
	headset-mode-setting = <0x500 0x500 1 0x1f0 0x800 0x800 0x20 0x44>;
	accdet-plugout-debounce = <1>;
	accdet-mic-mode = <1>;
	headset-eint-level-pol = <8>;
	headset-three-key-threshold = <0 80 220 400>;
	headset-three-key-threshold-CDD = <0 121 192 600>;
	headset-four-key-threshold = <0 58 121 192 400>;
	pinctrl-names = "default", "state_eint_as_int";
	pinctrl-0 = <&accdet_pins_default>;
	pinctrl-1 = <&accdet_pins_eint_as_int>;
	status = "okay";
};
&pio {
	accdet_pins_default: accdetdefault {
	};
	accdet_pins_eint_as_int: accdeteint@0 {
		pins_cmd_dat {
			pinmux = <PINMUX_GPIO9__FUNC_GPIO9>;
			slew-rate = <0>;
			bias-disable;
		};
	};
};
/* accdet end */

/* FINGERPRINT start */
&spi0 {
	#address-cells = <1>;
	#size-cells = <0>;
	fingerprint@0 {
		compatible = "goodix,goodix-fp";
		reg = <0>;
		spi-max-frequency = <8000000>;
		netlink-event = <30>;
		status = "okay";
	};
};

&goodix_fp {
	pinctrl-names = "default", "reset_high", "reset_low";
	pinctrl-0 = <&fingerprint_default>;
	pinctrl-1 = <&fingerprint_reset_high>;
	pinctrl-2 = <&fingerprint_reset_low>;
	status = "okay";
};

&pio {
	fingerprint_default: state_default {
	};
	fingerprint_reset_high: state_reset_high {
		pins_cmd_dat {
			pinmux = <PINMUX_GPIO172__FUNC_GPIO172>;
			slew-rate = <1>;
			output-high;
		};
	};
	fingerprint_reset_low: state_reset_low {
		pins_cmd_dat {
			pinmux = <PINMUX_GPIO172__FUNC_GPIO172>;
			slew-rate = <1>;
			output-low;
		};
	};
};
/* FINGERPRINT end */

/* IRTX GPIO end */
&irtx_pwm {
	pinctrl-names = "irtx_gpio_led_default", "irtx_gpio_led_set";
	pinctrl-0 = <&irtx_gpio_led_default>;
	pinctrl-1 = <&irtx_gpio_led_set>;
	status = "okay";
};
&pio {
	irtx_gpio_led_default:irtx_gpio_led_def@gpio90 {
		pins_cmd_dat {
			pinmux = <PINMUX_GPIO90__FUNC_GPIO90>;
			slew-rate = <1>;
			bias-disable;
			output-low;
			input-schmitt-enable = <0>;
		};
	};

	irtx_gpio_led_set:irtx_gpio_led_set@gpio90 {
		pins_cmd_dat {
			pinmux = <PINMUX_GPIO90__FUNC_PWM0>;
			slew-rate = <1>;
			output-high;
		};
	};
};
/* IRTX GPIO Settings -End */

/* AUDIO GPIO standardization */
&audgpio {
	pinctrl-names = "aud_clk_mosi_off",
			"aud_clk_mosi_on",
			"aud_clk_miso_off",
			"aud_clk_miso_on",
			"aud_dat_mosi_off",
			"aud_dat_mosi_on",
			"aud_dat_miso_off",
			"aud_dat_miso_on",
			"aud_smartpa_off",
			"aud_smartpa_on";
	pinctrl-0 = <&aud_clk_mosi_off>;
	pinctrl-1 = <&aud_clk_mosi_on>;
	pinctrl-2 = <&aud_clk_miso_off>;
	pinctrl-3 = <&aud_clk_miso_on>;
	pinctrl-4 = <&aud_dat_mosi_off>;
	pinctrl-5 = <&aud_dat_mosi_on>;
	pinctrl-6 = <&aud_dat_miso_off>;
	pinctrl-7 = <&aud_dat_miso_on>;
	pinctrl-8 = <&aud_pins_smartpa_off>;
	pinctrl-9 = <&aud_pins_smartpa_on>;
	status = "okay";
};

&pio {
	aud_clk_mosi_off: aud_clk_mosi_off {
		pins_cmd0_dat {
			pinmux = <PINMUX_GPIO136__FUNC_GPIO136>;
		};
	};

	aud_clk_mosi_on: aud_clk_mosi_on {
		pins_cmd0_dat {
			pinmux = <PINMUX_GPIO136__FUNC_AUD_CLK_MOSI>;
		};
	};

	aud_clk_miso_off: aud_clk_miso_off {
		pins_cmd0_dat {
			pinmux = <PINMUX_GPIO140__FUNC_GPIO140>;
		};
	};

	aud_clk_miso_on: aud_clk_miso_on {
		pins_cmd0_dat {
			pinmux = <PINMUX_GPIO140__FUNC_AUD_CLK_MISO>;
		};
	};

	aud_dat_mosi_off: aud_dat_mosi_off {
		pins_cmd1_dat {
			pinmux = <PINMUX_GPIO138__FUNC_GPIO138>;
			input-enable;
			slew-rate = <0>;
			bias-disable;
		};
		pins_cmd2_dat {
			pinmux = <PINMUX_GPIO139__FUNC_GPIO139>;
			input-enable;
			slew-rate = <0>;
			bias-disable;
		};
	};

	aud_dat_mosi_on: aud_dat_mosi_on {
		pins_cmd1_dat {
			pinmux = <PINMUX_GPIO138__FUNC_AUD_DAT_MOSI0>;
		};
		pins_cmd2_dat {
			pinmux = <PINMUX_GPIO139__FUNC_AUD_DAT_MOSI1>;
		};
	};

	aud_dat_miso_off: aud_dat_miso_off {
		pins_cmd1_dat {
			pinmux = <PINMUX_GPIO142__FUNC_GPIO142>;
			input-enable;
			slew-rate = <0>;
			bias-disable;
		};
		pins_cmd2_dat {
			pinmux = <PINMUX_GPIO143__FUNC_GPIO143>;
			input-enable;
			slew-rate = <0>;
			bias-disable;
		};
	};

	aud_dat_miso_on: aud_dat_miso_on {
		pins_cmd1_dat {
			pinmux = <PINMUX_GPIO142__FUNC_AUD_DAT_MISO0>;
		};
		pins_cmd2_dat {
			pinmux = <PINMUX_GPIO143__FUNC_AUD_DAT_MISO1>;
		};
	};

	aud_pins_smartpa_off: aud_pins_smartpa_off {
		pins_cmd0_dat {
			pinmux = <PINMUX_GPIO17__FUNC_GPIO17>;
		};
		pins_cmd1_dat {
			pinmux = <PINMUX_GPIO18__FUNC_GPIO18>;
		};
		pins_cmd2_dat {
			pinmux = <PINMUX_GPIO19__FUNC_GPIO19>;
		};
		pins_cmd3_dat {
			pinmux = <PINMUX_GPIO20__FUNC_GPIO20>;
		};
	};

	aud_pins_smartpa_on: aud_pins_smartpa_on {
		pins_cmd0_dat {
			pinmux = <PINMUX_GPIO17__FUNC_I2S0_DI>;
		};
		pins_cmd1_dat {
			pinmux = <PINMUX_GPIO18__FUNC_I2S3_BCK>;
		};
		pins_cmd2_dat {
			pinmux = <PINMUX_GPIO19__FUNC_I2S3_LRCK>;
		};
		pins_cmd3_dat {
			pinmux = <PINMUX_GPIO20__FUNC_I2S3_DO>;
		};
	};
};
/* AUDIO end */

&keypad {
	pinctrl-names = "default";
	pinctrl-0 = <&kpd_pins_default>;
};

&pio {
	kpd_pins_default: kpdgpiodefault {
		pins_cmd_dat {
			pinmux = <PINMUX_GPIO93__FUNC_KPCOL0>;
			bias-pull-up = <MTK_PUPD_SET_R1R0_10>;
			output-low;
			input-schmitt-enable;
		};
	};
};

/* FLASHLIGHT GPIO standardization */
&odm {
	flashlights_sywt78: flashlights_sywt78 {
		compatible = "mediatek,flashlights_sywt78";
		pinctrl-names = "default",
				"flash_low",
				"flash_high",
				"torch_low",
				"torch_high";

		pinctrl-0 = <&flash_default>;
		pinctrl-1 = <&flash_en_pin0>;
		pinctrl-2 = <&flash_en_pin1>;
		pinctrl-3 = <&torch_en_pin0>;
		pinctrl-4 = <&torch_en_pin1>;

		status = "okay";
	};
};

&pio {
	flash_default: flash_default {
	};

	flash_en_pin0: flash_en_pin0 {
		pins_cmd_dat {
			pinmux = <PINMUX_GPIO21__FUNC_GPIO21>;
			slew-rate = <1>;
			output-low;
		};
	};

	flash_en_pin1: flash_en_pin1 {
		pins_cmd_dat {
			pinmux = <PINMUX_GPIO21__FUNC_GPIO21>;
			slew-rate = <1>;
			output-high;
		};
	};

	torch_en_pin0: torch_en_pin0 {
		pins_cmd_dat {
			pinmux = <PINMUX_GPIO22__FUNC_GPIO22>;
			slew-rate = <1>;
			output-low;
		};
	};

	torch_en_pin1: torch_en_pin1 {
		pins_cmd_dat {
			pinmux = <PINMUX_GPIO22__FUNC_GPIO22>;
			slew-rate = <1>;
			output-high;
		};
	};
};
/* FLASHLIGHT end */

#include <P98928AA2/cust.dtsi>
#include "mediatek/cust_mt8768_camera.dtsi"

&msdc1 {
	cd_level = /bits/ 8 <MSDC_CD_HIGH>;
};

&mtk_gauge {
	charger = <&mtk_charger_type>;
};

&charger {
	charger = <&mtk_charger_type>;
};

&mtk_charger_type {
	bc12_active = <1>;
};

&usb {
	charger = <&mtk_charger_type>;
};

&rt1711_type_c_port0 {
	charger = <&mtk_charger_type>;

	rt-tcpc,name = "type_c_port0";
	rt1711pd,intr_gpio = <&pio 25 0x0>;
	rt1711pd,intr_gpio_num = <25>;
	rt-tcpc,role_def = <5>; /* 1: SNK Only, 2: SRC Only, 3: DRP, 4: Try SRC, 5: Try SNK */
#if (CONFIG_MTK_GAUGE_VERSION == 30)
	rt-tcpc,notifier_supply_num = <3>;
#else
	rt-tcpc,notifier_supply_num = <2>;
#endif
	rt-tcpc,rp_level = <0>; /* 0: Default, 1: 1.5, 2: 3.0 */
	rt-tcpc,vconn_supply  = <1>;  /* 0: Never, 1: Always, */
};

&lk_charger {
	enable_anime;
	enable_pe_plus;
	enable_pd20_reset;
	power_path_support;
	max_charger_voltage = <6500000>;
	fast_charge_voltage = <3000000>;

	/* charging current */
	usb_charger_current = <500000>;
	ac_charger_current = <2500000>;
	ac_charger_input_current = <2000000>;
	non_std_ac_charger_current = <500000>;
	charging_host_charger_current = <1500000>;
	ta_ac_charger_current = <3000000>;
	pd_charger_current = <500000>;

	/* battery temperature protection */
	temp_t4_threshold = <50>;
	temp_t3_threshold = <45>;
	temp_t1_threshold = <0>;
};

&board_id {
	board_id1-gpios = <&pio 163 0>;
	board_id2-gpios = <&pio 164 0>;
	board_id3-gpios = <&pio 165 0>;
	board_id4-gpios = <&pio 166 0>;
	board_id5-gpios = <&pio 176 0>;
	status = "okay";
};

/*End of this file, DO NOT ADD ANYTHING HERE*/
